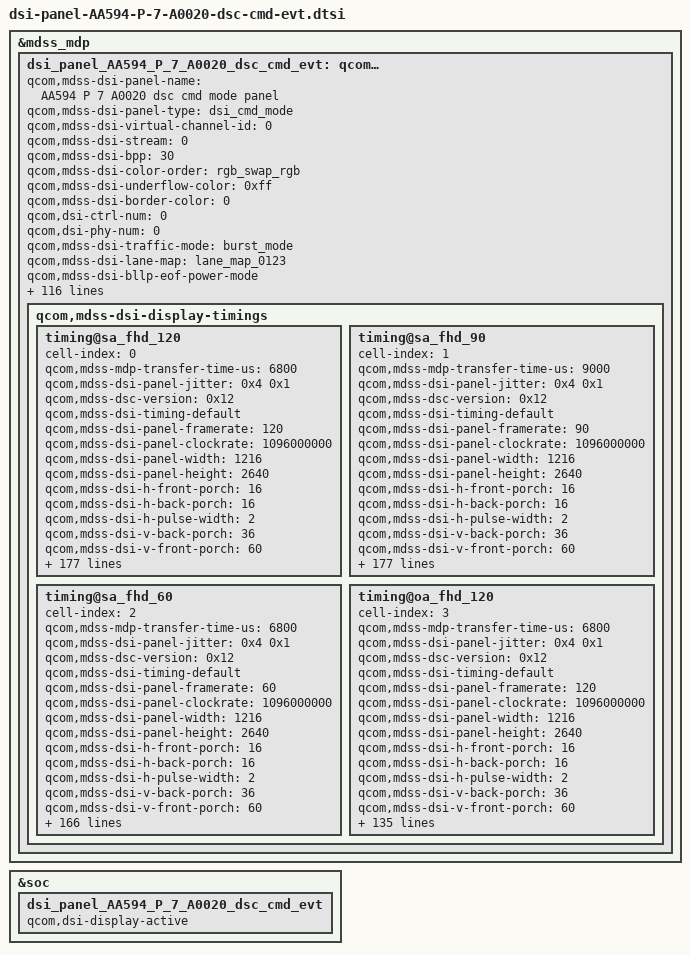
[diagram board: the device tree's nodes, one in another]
&mdss_mdp {
	dsi_panel_AA594_P_7_A0020_dsc_cmd_evt: qcom,mdss_dsi_panel_AA594_P_7_A0020_dsc_cmd_evt {
		qcom,mdss-dsi-panel-name = "AA594 P 7 A0020 dsc cmd mode panel";
		qcom,mdss-dsi-panel-type = "dsi_cmd_mode";
		qcom,mdss-dsi-virtual-channel-id = <0>;
		qcom,mdss-dsi-stream = <0>;
		qcom,mdss-dsi-bpp = <30>;
		qcom,mdss-dsi-color-order = "rgb_swap_rgb";
		qcom,mdss-dsi-underflow-color = <0xff>;
		qcom,mdss-dsi-border-color = <0>;
		qcom,dsi-ctrl-num = <0>;
		qcom,dsi-phy-num = <0>;
		qcom,mdss-dsi-traffic-mode = "burst_mode";
		qcom,mdss-dsi-lane-map = "lane_map_0123";
		qcom,mdss-dsi-bllp-eof-power-mode;
		qcom,mdss-dsi-bllp-power-mode;
		qcom,mdss-dsi-lane-0-state;
		qcom,mdss-dsi-lane-1-state;
		qcom,mdss-dsi-lane-2-state;
		qcom,mdss-dsi-lane-3-state;
		qcom,mdss-dsi-dma-trigger = "trigger_sw";
		qcom,mdss-dsi-dma-schedule-line = <1>;
		qcom,mdss-dsi-dma-schedule-window = <10>;
		qcom,mdss-dsi-mdp-trigger = "none";
		qcom,mdss-dsi-reset-sequence = <1 10>, <0 5>, <1 25>;
		qcom,mdss-dsi-te-pin-select = <1>;
		qcom,mdss-dsi-te-dcs-command = <1>;
		qcom,mdss-pan-physical-width-dimension = <67>;
		qcom,mdss-pan-physical-height-dimension = <146>;
		qcom,mdss-dsi-init-delay-us = <1000>;
		qcom,mdss-dsi-te-check-enable;
		qcom,mdss-dsi-te-using-te-pin;
		//qcom,mdss-dsi-lp11-init;
		qcom,mdss-dsi-wr-mem-start = <0x2C>;
		qcom,mdss-dsi-wr-mem-continue = <0x3C>;
		qcom,mdss-dsi-panel-jitter = <0x4 0x1>;
		qcom,mdss-bl-high2bit;
		/* HDR Setting */
		qcom,mdss-dsi-panel-hdr-enabled;
		qcom,mdss-dsi-panel-hdr-color-primaries = <15635 16450 34000 16000 13250 34500 7500 3000>;
		//update for [MPC15]android.mediapc.cts.PerformanceClassTest#testDisplayHdr pass
		//qcom,mdss-dsi-panel-peak-brightness = <5400000>;
		qcom,mdss-dsi-panel-peak-brightness = <20000000>;
		qcom,mdss-dsi-panel-average-brightness = <2000000>;
		qcom,mdss-dsi-panel-blackness-level = <4000>;

		qcom,mdss-dsi-display-timings {
			timing@sa_fhd_120 {
				#include "dsi-panel-AA594-P-7-A0020-common.dtsi"
				#include "dsi-panel-AA594-P-7-A0020-common-effect.dtsi"
				cell-index = <0>;
				qcom,mdss-mdp-transfer-time-us = <6800>;
				qcom,mdss-dsi-panel-jitter = <0x4 0x1>;
				qcom,mdss-dsc-version = <0x12>;
				qcom,mdss-dsi-timing-default;
				qcom,mdss-dsi-panel-framerate = <120>;
				qcom,mdss-dsi-panel-clockrate = <1096000000>;
				qcom,mdss-dsi-panel-width = <1216>;
				qcom,mdss-dsi-panel-height = <2640>;

				qcom,mdss-dsi-h-front-porch = <16>;
				qcom,mdss-dsi-h-back-porch = <16>;
				qcom,mdss-dsi-h-pulse-width = <2>;
				qcom,mdss-dsi-v-back-porch = <36>;
				qcom,mdss-dsi-v-front-porch = <60>;
				qcom,mdss-dsi-v-pulse-width = <4>;
				qcom,mdss-dsi-h-sync-pulse = <0>;

				oplus,ofp-backlight-on-period = <1>;

				qcom,mdss-dsi-timing-switch-command = [
					/* Switch To 120Hz(Normal 1+18 pulse) */
					39 00 00 40 00 00 04 FF 5A A5 53
					39 00 00 40 00 00 03 85 CC E1
					39 00 00 40 00 00 04 FF 5A A5 00
					15 00 00 40 00 00 02 60 00 //120hz
					39 00 00 40 00 00 04 FF 5A A5 2D
					39 00 00 40 00 00 03 83 00 00
					15 00 00 40 00 00 02 F2 00
					39 00 00 00 00 00 04 FF 5A A5 00
				];
				qcom,mdss-dsi-on-command = [
					/* DSC setting */
					39 00 00 40 00 00 04 FF 5A A5 1F
					39 00 00 40 00 00 04 83 2C 00 4E
					39 00 00 40 00 00 04 84 1B 00 4E
					39 00 00 00 00 00 04 85 35 00 4E
					39 00 00 40 00 00 04 FF 5A A5 07
					15 00 00 40 00 00 02 8A 01
					39 00 00 40 00 00 03 8B 21 A0
					39 00 00 40 00 00 64 80 00 00 00 00 00
							12 00 00 AB 21 00 0A 50 04 C0 00 14
							02 60 02 60 01 55 01 D3 00 0A 01 08
							00 33 00 0D 05 7A 19 5A 08 00 0B F0
							07 10 20 00 06 0F 0F 33 0E 1C 2A 38
							46 54 62 69 70 77 79 7B 7D 7E 00 82
							11 40 19 C0 22 3E 32 7C 3A BA 3A F8
							3B 38 3B 38 3B 76 4B 76 4B 74 4B 74
							5B B4 73 F4 01 00 00 00 00 00
					15 00 00 40 00 00 02 91 03
					39 00 00 40 00 00 04 FF 5A A5 14
					15 00 00 40 00 00 02 80 00
					15 00 00 40 00 00 02 82 01
					39 00 00 00 00 00 04 FF 5A A5 00
					/* Common setting */
					39 00 00 40 00 00 04 FF 5A A5 08
					15 00 00 40 00 00 02 C8 62
					39 00 00 40 00 00 04 FF 5A A5 21
					15 00 00 40 00 00 02 A4 18
					39 00 00 40 00 00 04 FF 5A A5 00
					15 00 00 40 00 00 02 5E 01
					15 00 00 40 00 00 02 60 00
					15 00 00 40 00 00 02 61 07
					15 00 00 40 00 00 02 6D 01
					05 00 00 40 00 00 01 35
					15 00 00 40 00 00 02 53 20
					39 00 00 40 00 00 04 FF 5A A5 06
					15 00 00 40 00 00 02 C6 01 //1bit ESD Check
					39 00 00 40 00 00 04 FF 5A A5 08
					15 00 00 40 00 00 02 D2 05
					15 00 00 40 00 00 02 D3 01
					39 00 00 40 00 00 0A ED FF FF FF 0F 07 FF CF 45 FF //Golden CRC
					39 00 00 40 00 00 09 EE FF FD C1 F8 21 00 80 50
					39 00 00 40 00 00 04 FF 5A A5 20
					15 00 00 40 00 00 02 BC 07 //GPO1 TEST TE
					15 00 00 40 00 00 02 BD 06 //GPO0 SYNC TE
					39 00 00 00 00 00 04 FF 5A A5 00
					/* Corner/Hole/Edge OFF */
					39 00 00 40 00 00 04 FF 5A A5 17
					15 00 00 40 00 00 02 A0 0C
					39 00 00 00 00 00 04 FF 5A A5 00
					/* Switch To 120Hz(Normal 1+18 pulse) */
					39 00 00 40 00 00 04 FF 5A A5 53
					39 00 00 40 00 00 03 85 CC E1
					39 00 00 40 00 00 04 FF 5A A5 00
					15 00 00 40 00 00 02 60 00 //120hz
					39 00 00 40 00 00 04 FF 5A A5 2D
					39 00 00 40 00 00 03 83 00 00
					15 00 00 40 00 00 02 F2 00
					39 00 00 00 00 00 04 FF 5A A5 00
					39 00 00 40 00 00 04 FF 5A A5 1E
					15 00 00 40 00 00 02 9B 02
					39 00 00 00 00 00 04 FF 5A A5 00
					05 00 00 00 78 00 01 11
					05 00 00 00 00 00 01 29
				];
				qcom,mdss-dsi-optimize-on-command = [
					/* DSC setting */
					39 00 00 40 00 00 04 FF 5A A5 07
					15 00 00 40 00 00 02 8A 01
					39 00 00 40 00 00 03 8B 21 A0
					39 00 00 40 00 00 64 80 00 00 00 00 00
							12 00 00 AB 21 00 0A 50 04 C0 00 14
							02 60 02 60 01 55 01 D3 00 0A 01 08
							00 33 00 0D 05 7A 19 5A 08 00 0B F0
							07 10 20 00 06 0F 0F 33 0E 1C 2A 38
							46 54 62 69 70 77 79 7B 7D 7E 00 82
							11 40 19 C0 22 3E 32 7C 3A BA 3A F8
							3B 38 3B 38 3B 76 4B 76 4B 74 4B 74
							5B B4 73 F4 01 00 00 00 00 00
					15 00 00 40 00 00 02 91 03
					39 00 00 40 00 00 04 FF 5A A5 14
					15 00 00 40 00 00 02 80 00
					15 00 00 40 00 00 02 82 01
					39 00 00 00 00 00 04 FF 5A A5 00
					/* Common setting */
					39 00 00 40 00 00 04 FF 5A A5 08
					15 00 00 40 00 00 02 C8 62
					39 00 00 40 00 00 04 FF 5A A5 21
					15 00 00 40 00 00 02 A4 18
					39 00 00 40 00 00 04 FF 5A A5 00
					15 00 00 40 00 00 02 5E 01
					15 00 00 40 00 00 02 60 00
					15 00 00 40 00 00 02 61 07
					15 00 00 40 00 00 02 6D 01
					05 00 00 40 00 00 01 35
					15 00 00 40 00 00 02 53 20
					39 00 00 40 00 00 04 FF 5A A5 06
					15 00 00 40 00 00 02 C6 01 //1bit ESD Check
					39 00 00 40 00 00 04 FF 5A A5 08
					15 00 00 40 00 00 02 D2 05
					15 00 00 40 00 00 02 D3 01
					39 00 00 40 00 00 0A ED FF FF FF 0F 07 FF CF 45 FF //Golden CRC
					39 00 00 40 00 00 09 EE FF FD C1 F8 21 00 80 50
					39 00 00 40 00 00 04 FF 5A A5 20
					15 00 00 40 00 00 02 BC 07 //GPO1 TEST TE
					15 00 00 40 00 00 02 BD 06 //GPO0 SYNC TE
					39 00 00 00 00 00 04 FF 5A A5 00
					/* Corner/Hole/Edge OFF */
					39 00 00 40 00 00 04 FF 5A A5 17
					15 00 00 40 00 00 02 A0 0C
					39 00 00 00 00 00 04 FF 5A A5 00
					/* Switch To 120Hz(Normal 1+18 pulse) */
					39 00 00 40 00 00 04 FF 5A A5 4E
					39 00 00 40 00 00 5B CF 00 14 14 14 14 14 08 88 88 00 00 00 00 00 00 00 00 00 00 08 08 08 08 08 08 88 88 00 00 00 00 00 00 00 00 00 00 08 08 08 08 08 08 88 88 00 00 00 00 00 00 00 00 00 00 00 00 00 00 00 08 88 88 00 00 00 00 00 00 00 00 00 00 00 00 00 00 00 08 88 88 00 00 00 00 00 00 00 00 00
					39 00 00 40 00 00 5B D0 00 0F 0F 0F 0F 0F 08 88 88 00 00 00 00 00 00 00 00 00 00 0B 0B 0B 0B 0B 08 88 88 00 00 00 00 00 00 00 00 00 00 0B 0B 0B 0B 0B 08 88 88 00 00 00 00 00 00 00 00 00 00 07 07 07 07 07 08 88 88 00 00 00 00 00 00 00 00 00 00 07 07 07 07 07 08 88 88 00 00 00 00 00 00 00 00 00
					39 00 00 40 00 00 04 FF 5A A5 53
					39 00 00 40 00 00 03 85 CC E1
					39 00 00 40 00 00 04 FF 5A A5 00
					15 00 00 40 00 00 02 60 00 //120Hz
					39 00 00 40 00 00 04 FF 5A A5 2D
					39 00 00 40 00 00 03 83 00 00
					15 00 00 40 00 00 02 F2 00
					39 00 00 00 00 00 04 FF 5A A5 00
					39 00 00 40 00 00 04 FF 5A A5 1E
					39 00 00 40 00 00 04 C1 10 9C C9
					39 00 00 40 00 00 08 C2 FF FF FF 60 60 63 63
					39 00 00 40 00 00 04 FF 5A A5 1F
					39 00 00 40 00 00 07 C1 00 00 00 00 1F FF
					39 00 00 00 00 00 1F C2 AB D7 D8 E2 1F FF 25 27 FF FF FF FF FF FF FF FF FF FF FF FF FF FF FF FF FF FF FF FF FF FF
					05 00 00 00 78 00 01 11
					05 00 00 00 00 00 01 29
				];
				qcom,mdss-dsi-off-command = [
					05 00 00 00 14 00 01 28
					05 00 00 00 78 00 01 10
				];
				qcom,mdss-dsi-hbm-off-command = [
					39 00 00 00 00 00 03 51 0D BB
				];
				qcom,mdss-dsi-hbm-on-command = [
					39 00 00 00 00 00 03 51 0E E0
				];
				/* pwm */
				qcom,mdss-dsi-pwm-switch-mode1-command = [
					39 00 00 40 00 00 04 FF 5A A5 51
					39 00 00 40 00 00 07 A0 AF AF AF AF 22 22
					39 00 00 40 00 00 07 A1 AF AF AF AF 22 22
					39 00 00 40 00 00 07 A2 AF AF AF AF 22 22
					39 00 00 40 00 00 07 A3 AF AF AF AF 22 22
					39 00 00 40 00 00 07 A4 AF AF AF AF 22 22
					39 00 00 40 00 00 07 A5 AF AF B9 B9 22 22
					39 00 00 40 00 00 07 A6 B3 B3 B6 B6 22 22
					39 00 00 40 00 00 07 A7 D4 D4 00 00 22 00
					39 00 00 40 00 00 04 FF 5A A5 52
					39 00 00 40 00 00 07 80 5E 2C B4 AA 11 00
					39 00 00 40 00 00 07 81 A0 A0 96 96 00 00
					39 00 00 40 00 00 07 82 8C 8C 82 82 00 00
					39 00 00 40 00 00 07 83 82 78 78 6E 00 00
					39 00 00 40 00 00 07 84 6E 64 64 64 00 00
					39 00 00 40 00 00 07 85 5A 5A 5C 5C 00 00
					39 00 00 40 00 00 07 86 5D 5D 5D 5D 00 00
					39 00 00 40 00 00 07 87 52 52 00 00 11 00
					39 00 00 40 00 00 04 FF 5A A5 00
					15 00 00 40 00 00 02 60 00 //120hz
					39 00 00 40 00 00 04 FF 5A A5 2D
					39 00 00 40 00 00 03 83 00 00
					15 00 00 40 00 00 02 F2 00
					39 00 00 40 00 00 04 FF 5A A5 53
					39 00 00 40 00 00 03 85 CC E1
					39 00 00 00 00 00 04 FF 5A A5 00
				];
				qcom,mdss-dsi-pwm-switch-mode2-command = [
					39 00 00 40 00 00 04 FF 5A A5 51
					39 00 00 40 00 00 07 A0 AF AF AF AF 22 22
					39 00 00 40 00 00 07 A1 AF AF AF AF 22 22
					39 00 00 40 00 00 07 A2 AF AF AF AF 22 22
					39 00 00 40 00 00 07 A3 AF AF AF AF 22 22
					39 00 00 40 00 00 07 A4 AF AF AF AF 22 22
					39 00 00 40 00 00 07 A5 AF AF BC BC 22 22
					39 00 00 40 00 00 07 A6 C0 C0 C0 C0 22 22
					39 00 00 40 00 00 07 A7 CA CA 00 00 22 00
					39 00 00 40 00 00 04 FF 5A A5 52
					39 00 00 40 00 00 07 80 5E 2C B4 AA 11 00
					39 00 00 40 00 00 07 81 A0 A0 96 96 00 00
					39 00 00 40 00 00 07 82 8C 8C 82 82 00 00
					39 00 00 40 00 00 07 83 82 78 78 6E 00 00
					39 00 00 40 00 00 07 84 6E 64 64 64 00 00
					39 00 00 40 00 00 07 85 5A 5A 5B 5B 00 00
					39 00 00 40 00 00 07 86 5C 5C 5C 5C 00 00
					39 00 00 40 00 00 07 87 4D 4D 00 00 11 00
					39 00 00 40 00 00 04 FF 5A A5 53
					39 00 00 40 00 00 03 85 CC E3
					39 00 00 40 00 00 04 FF 5A A5 00
					15 00 00 40 00 00 02 60 01 //DC 120hz
					39 00 00 40 00 00 04 FF 5A A5 2D
					39 00 00 40 00 00 03 84 00 00
					15 00 00 40 00 00 02 F2 00
					39 00 00 00 00 00 04 FF 5A A5 00
				];
				qcom,mdss-dsi-timming-switch-pwm-mode2-command = [
					39 00 00 40 00 00 04 FF 5A A5 53
					39 00 00 40 00 00 03 85 CC E3
					39 00 00 40 00 00 04 FF 5A A5 00
					15 00 00 40 00 00 02 60 01 //DC 120Hz
					39 00 00 40 00 00 04 FF 5A A5 2D
					39 00 00 40 00 00 03 84 00 00
					15 00 00 40 00 00 02 F2 00
					39 00 00 00 00 00 04 FF 5A A5 00
				];
				qcom,mdss-dsi-pwm-switch-mode2-panel-on-command = [
					39 00 00 40 00 00 04 FF 5A A5 51
					39 00 00 40 00 00 07 A0 AF AF AF AF 22 22
					39 00 00 40 00 00 07 A1 AF AF AF AF 22 22
					39 00 00 40 00 00 07 A2 AF AF AF AF 22 22
					39 00 00 40 00 00 07 A3 AF AF AF AF 22 22
					39 00 00 40 00 00 07 A4 AF AF AF AF 22 22
					39 00 00 40 00 00 07 A5 AF AF BC BC 22 22
					39 00 00 40 00 00 07 A6 C0 C0 C0 C0 22 22
					39 00 00 40 00 00 07 A7 CA CA 00 00 22 00
					39 00 00 40 00 00 04 FF 5A A5 52
					39 00 00 40 00 00 07 80 5E 2C B4 AA 11 00
					39 00 00 40 00 00 07 81 A0 A0 96 96 00 00
					39 00 00 40 00 00 07 82 8C 8C 82 82 00 00
					39 00 00 40 00 00 07 83 82 78 78 6E 00 00
					39 00 00 40 00 00 07 84 6E 64 64 64 00 00
					39 00 00 40 00 00 07 85 5A 5A 5B 5B 00 00
					39 00 00 40 00 00 07 86 5C 5C 5C 5C 00 00
					39 00 00 40 00 00 07 87 4D 4D 00 00 11 00
					39 00 00 40 00 00 04 FF 5A A5 53
					39 00 00 40 00 00 03 85 CC E3
					39 00 00 40 00 00 04 FF 5A A5 00
					15 00 00 40 00 00 02 60 01 //DC 120hz
					39 00 00 40 00 00 04 FF 5A A5 2D
					39 00 00 40 00 00 03 84 00 00
					15 00 00 40 00 00 02 F2 00
					39 00 00 00 00 00 04 FF 5A A5 00
				];
				qcom,mdss-dsi-lhbm-pressed-icon-on-command = [
					39 00 00 40 00 00 04 FF 5A A5 00
					15 00 00 40 00 00 02 96 09
					15 00 00 40 00 00 02 97 5B
					39 00 00 00 00 00 02 6E 03
				];
				qcom,mdss-dsi-lhbm-pressed-icon-off-command = [
					39 00 00 40 00 00 04 FF 5A A5 00
					39 00 00 00 00 00 02 6E 00
				];
				qcom,mdss-dsi-lp1-command = [
					39 00 00 40 00 00 04 FF 5A A5 00
					15 00 00 40 00 00 01 39
					39 00 00 40 00 00 04 FF 5A A5 2D
					15 00 00 40 00 00 03 8A 00 00
					/* AOD lv switch */
					39 00 00 40 00 00 04 FF 5A A5 00
					39 00 00 00 00 00 05 51 0D BB 0D BB
				];
				qcom,mdss-dsi-nolp-command = [
					39 00 00 40 00 00 04 FF 5A A5 00
					15 00 00 40 00 00 01 38
					39 00 00 00 00 00 05 51 00 00 00 00
				];
				qcom,mdss-dsi-aod-off-pwm-mode2-command = [
				];
				qcom,mdss-dsi-aod-off-compensation-command = [

				];
				qcom,mdss-dsi-aod-off-compensation-onepulse-command = [

				];
				qcom,mdss-dsi-aod-high-mode-command = [
					39 00 00 40 00 00 04 FF 5A A5 00
					39 00 00 00 00 00 05 51 0D BB 0D BB
				];
				qcom,mdss-dsi-aod-low-mode-command = [
					39 00 00 40 00 00 04 FF 5A A5 00
					39 00 00 00 00 00 05 51 0D BB 00 03
				];
				qcom,mdss-dsi-ultra-low-power-aod-on-command = [
					39 00 00 40 00 00 04 FF 5A A5 2D
					39 00 00 40 00 00 03 8A 02 00
					39 00 00 00 00 00 04 FF 5A A5 00
				];
				qcom,mdss-dsi-ultra-low-power-aod-off-command = [
					39 00 00 40 00 00 04 FF 5A A5 2D
					39 00 00 40 00 00 03 8A 00 00
					39 00 00 00 00 00 04 FF 5A A5 00
				];
				qcom,mdss-dsi-hbm-max-command = [
					39 00 00 00 00 00 03 51 10 ED
				];
				qcom,mdss-dsi-hbm-exit-max-command = [
					39 00 00 00 00 00 03 51 0F FE
				];
				qcom,mdss-dsi-lp1-command-state = "dsi_hs_mode";
				qcom,mdss-dsi-nolp-command-state = "dsi_hs_mode";
				qcom,mdss-dsi-aod-off-pwm-mode2-command-state = "dsi_hs_mode";
				qcom,mdss-dsi-aod-off-compensation-command-state = "dsi_lp_mode";
				qcom,mdss-dsi-aod-off-compensation-onepulse-command-state = "dsi_lp_mode";
				qcom,mdss-dsi-nolp-hpwm-command-state = "dsi_lp_mode";
				qcom,mdss-dsi-hbm-on-command-state = "dsi_hs_mode";
				qcom,mdss-dsi-hbm-off-command-state = "dsi_hs_mode";
				qcom,mdss-dsi-panel-read-register-open-state = "dsi_lp_mode";
				qcom,mdss-dsi-panel-read-register-close-state = "dsi_lp_mode";
				qcom,mdss-dsi-lhbm-pressed-icon-gamma-command-state = "dsi_lp_mode";
				qcom,mdss-dsi-lhbm-pressed-icon-grayscale-command-state = "dsi_lp_mode";
				qcom,mdss-dsi-lhbm-pressed-icon-on-command-state = "dsi_lp_mode";
				qcom,mdss-dsi-lhbm-pressed-icon-off-command-state = "dsi_lp_mode";
				qcom,mdss-dsi-lhbm-dbv-alpha-command-state = "dsi_hs_mode";

				qcom,mdss-dsi-reset-scanline-command-state = "dsi_hs_mode";
				qcom,mdss-dsi-recovery-scanline-command-state = "dsi_hs_mode";

				qcom,mdss-dsi-osc-track-on-command-state = "dsi_hs_mode";
				qcom,mdss-dsi-osc-track-off-command-state = "dsi_hs_mode";
				qcom,mdss-dsi-hbm-max-command-state = "dsi_hs_mode";
				qcom,mdss-dsi-hbm-exit-max-command-state = "dsi_hs_mode";

				qcom,lm-split = <608 608>;
				qcom,compression-mode = "dsc";
				qcom,mdss-dsc-encoders = <2>;
				qcom,mdss-dsc-slice-height = <20>;
				qcom,mdss-dsc-slice-width = <608>;
				qcom,mdss-dsc-slice-per-pkt = <2>;
				qcom,mdss-dsc-bit-per-component = <10>;
				qcom,mdss-dsc-bit-per-pixel = <8>;
				qcom,mdss-dsc-block-prediction-enable;
			};
			timing@sa_fhd_90 {
				#include "dsi-panel-AA594-P-7-A0020-common.dtsi"
				#include "dsi-panel-AA594-P-7-A0020-common-effect.dtsi"
				cell-index = <1>;
				qcom,mdss-mdp-transfer-time-us = <9000>;
				qcom,mdss-dsi-panel-jitter = <0x4 0x1>;
				qcom,mdss-dsc-version = <0x12>;
				qcom,mdss-dsi-timing-default;
				qcom,mdss-dsi-panel-framerate = <90>;
				qcom,mdss-dsi-panel-clockrate = <1096000000>;
				qcom,mdss-dsi-panel-width = <1216>;
				qcom,mdss-dsi-panel-height = <2640>;

				qcom,mdss-dsi-h-front-porch = <16>;
				qcom,mdss-dsi-h-back-porch = <16>;
				qcom,mdss-dsi-h-pulse-width = <2>;
				qcom,mdss-dsi-v-back-porch = <36>;
				qcom,mdss-dsi-v-front-porch = <60>;
				qcom,mdss-dsi-v-pulse-width = <4>;
				qcom,mdss-dsi-h-sync-pulse = <0>;

				oplus,ofp-backlight-on-period = <1>;
				oplus,apollo-panel-async-bl-delay = <6000>;

				qcom,mdss-dsi-timing-switch-command = [
					/* Switch To 90Hz (Normal 1+24 pulse) */
					39 00 00 40 00 00 04 FF 5A A5 53
					39 00 00 40 00 00 03 85 CC E1
					39 00 00 40 00 00 04 FF 5A A5 00
					15 00 00 40 00 00 02 60 02 //90hz
					39 00 00 40 00 00 04 FF 5A A5 2D
					39 00 00 40 00 00 03 85 00 00
					15 00 00 40 00 00 02 F2 00
					39 00 00 00 00 00 04 FF 5A A5 00
				];
				qcom,mdss-dsi-on-command = [
					/* DSC setting */
					39 00 00 40 00 00 04 FF 5A A5 1F
					39 00 00 40 00 00 04 83 2C 00 4E
					39 00 00 40 00 00 04 84 1B 00 4E
					39 00 00 00 00 00 04 85 35 00 4E
					39 00 00 40 00 00 04 FF 5A A5 07
					15 00 00 40 00 00 02 8A 01
					39 00 00 40 00 00 03 8B 21 A0
					39 00 00 40 00 00 64 80 00 00 00 00 00
							12 00 00 AB 21 00 0A 50 04 C0 00 14
							02 60 02 60 01 55 01 D3 00 0A 01 08
							00 33 00 0D 05 7A 19 5A 08 00 0B F0
							07 10 20 00 06 0F 0F 33 0E 1C 2A 38
							46 54 62 69 70 77 79 7B 7D 7E 00 82
							11 40 19 C0 22 3E 32 7C 3A BA 3A F8
							3B 38 3B 38 3B 76 4B 76 4B 74 4B 74
							5B B4 73 F4 01 00 00 00 00 00
					15 00 00 40 00 00 02 91 03
					39 00 00 40 00 00 04 FF 5A A5 14
					15 00 00 40 00 00 02 80 00
					15 00 00 40 00 00 02 82 01
					39 00 00 00 00 00 04 FF 5A A5 00
					/* Common setting */
					39 00 00 40 00 00 04 FF 5A A5 08
					15 00 00 40 00 00 02 C8 62
					39 00 00 40 00 00 04 FF 5A A5 21
					15 00 00 40 00 00 02 A4 18
					39 00 00 40 00 00 04 FF 5A A5 00
					15 00 00 40 00 00 02 5E 01
					15 00 00 40 00 00 02 60 00
					15 00 00 40 00 00 02 61 07
					15 00 00 40 00 00 02 6D 01
					05 00 00 40 00 00 01 35
					15 00 00 40 00 00 02 53 20
					39 00 00 40 00 00 04 FF 5A A5 06
					15 00 00 40 00 00 02 C6 01 //1bit ESD Check
					39 00 00 40 00 00 04 FF 5A A5 08
					15 00 00 40 00 00 02 D2 05
					15 00 00 40 00 00 02 D3 01
					39 00 00 40 00 00 0A ED FF FF FF 0F 07 FF CF 45 FF //Golden CRC
					39 00 00 40 00 00 09 EE FF FD C1 F8 21 00 80 50
					39 00 00 40 00 00 04 FF 5A A5 20
					15 00 00 40 00 00 02 BC 07 //GPO1 TEST TE
					15 00 00 40 00 00 02 BD 06 //GPO0 SYNC TE
					39 00 00 00 00 00 04 FF 5A A5 00
					/* Corner/Hole/Edge OFF */
					39 00 00 40 00 00 04 FF 5A A5 17
					15 00 00 40 00 00 02 A0 0C
					39 00 00 00 00 00 04 FF 5A A5 00
					/* Switch To 90Hz (Normal 1+24 pulse) */
					39 00 00 40 00 00 04 FF 5A A5 53
					39 00 00 40 00 00 03 85 CC E1
					39 00 00 40 00 00 04 FF 5A A5 00
					15 00 00 40 00 00 02 60 02 //90hz
					39 00 00 40 00 00 04 FF 5A A5 2D
					39 00 00 40 00 00 03 85 00 00
					15 00 00 40 00 00 02 F2 00
					39 00 00 00 00 00 04 FF 5A A5 00
					39 00 00 40 00 00 04 FF 5A A5 1E
					15 00 00 40 00 00 02 9B 02
					39 00 00 00 00 00 04 FF 5A A5 00
					05 00 00 00 78 00 01 11
					05 00 00 00 00 00 01 29
				];
				qcom,mdss-dsi-optimize-on-command = [
					/* DSC setting */
					39 00 00 40 00 00 04 FF 5A A5 07
					15 00 00 40 00 00 02 8A 01
					39 00 00 40 00 00 03 8B 21 A0
					39 00 00 40 00 00 64 80 00 00 00 00 00
							12 00 00 AB 21 00 0A 50 04 C0 00 14
							02 60 02 60 01 55 01 D3 00 0A 01 08
							00 33 00 0D 05 7A 19 5A 08 00 0B F0
							07 10 20 00 06 0F 0F 33 0E 1C 2A 38
							46 54 62 69 70 77 79 7B 7D 7E 00 82
							11 40 19 C0 22 3E 32 7C 3A BA 3A F8
							3B 38 3B 38 3B 76 4B 76 4B 74 4B 74
							5B B4 73 F4 01 00 00 00 00 00
					15 00 00 40 00 00 02 91 03
					39 00 00 40 00 00 04 FF 5A A5 14
					15 00 00 40 00 00 02 80 00
					15 00 00 40 00 00 02 82 01
					39 00 00 00 00 00 04 FF 5A A5 00
					/* Common setting */
					39 00 00 40 00 00 04 FF 5A A5 08
					15 00 00 40 00 00 02 C8 62
					39 00 00 40 00 00 04 FF 5A A5 21
					15 00 00 40 00 00 02 A4 18
					39 00 00 40 00 00 04 FF 5A A5 00
					15 00 00 40 00 00 02 5E 01
					15 00 00 40 00 00 02 60 00
					15 00 00 40 00 00 02 61 07
					15 00 00 40 00 00 02 6D 01
					05 00 00 40 00 00 01 35
					15 00 00 40 00 00 02 53 20
					39 00 00 40 00 00 04 FF 5A A5 06
					15 00 00 40 00 00 02 C6 01 //1bit ESD Check
					39 00 00 40 00 00 04 FF 5A A5 08
					15 00 00 40 00 00 02 D2 05
					15 00 00 40 00 00 02 D3 01
					39 00 00 40 00 00 0A ED FF FF FF 0F 07 FF CF 45 FF //Golden CRC
					39 00 00 40 00 00 09 EE FF FD C1 F8 21 00 80 50
					39 00 00 40 00 00 04 FF 5A A5 20
					15 00 00 40 00 00 02 BC 07 //GPO1 TEST TE
					15 00 00 40 00 00 02 BD 06 //GPO0 SYNC TE
					39 00 00 00 00 00 04 FF 5A A5 00
					/* Corner/Hole/Edge OFF */
					39 00 00 40 00 00 04 FF 5A A5 17
					15 00 00 40 00 00 02 A0 0C
					39 00 00 00 00 00 04 FF 5A A5 00
					/* Switch To 90Hz (Normal 1+24 pulse) */
					39 00 00 40 00 00 04 FF 5A A5 4E
					39 00 00 40 00 00 5B CF 00 14 14 14 14 14 08 88 88 00 00 00 00 00 00 00 00 00 00 0A 0A 0A 0A 0A 08 88 88 00 00 00 00 00 00 00 00 00 00 0A 0A 0A 0A 0A 08 88 88 00 00 00 00 00 00 00 00 00 00 18 18 18 18 18 08 88 88 00 00 00 00 00 00 00 00 00 00 18 18 18 18 18 08 88 88 00 00 00 00 00 00 00 00 00
					39 00 00 40 00 00 5B D0 00 0F 0F 0F 0F 0F 08 88 88 00 00 00 00 00 00 00 00 00 00 0B 0B 0B 0B 0B 08 88 88 00 00 00 00 00 00 00 00 00 00 0B 0B 0B 0B 0B 08 88 88 00 00 00 00 00 00 00 00 00 00 0B 0B 0B 0B 0B 08 88 88 00 00 00 00 00 00 00 00 00 00 0B 0B 0B 0B 0B 08 88 88 00 00 00 00 00 00 00 00 00
					39 00 00 40 00 00 04 FF 5A A5 53
					39 00 00 40 00 00 03 85 CC E1
					39 00 00 40 00 00 04 FF 5A A5 00
					15 00 00 40 00 00 02 60 02 //90Hz
					39 00 00 40 00 00 04 FF 5A A5 2D
					39 00 00 40 00 00 03 85 00 00
					15 00 00 40 00 00 02 F2 00
					39 00 00 00 00 00 04 FF 5A A5 00
					39 00 00 40 00 00 04 FF 5A A5 1E
					39 00 00 40 00 00 04 C1 10 9C C9
					39 00 00 40 00 00 08 C2 FF FF FF 60 60 63 63
					39 00 00 40 00 00 04 FF 5A A5 1F
					39 00 00 40 00 00 07 C1 00 00 00 00 1F FF
					39 00 00 00 00 00 1F C2 AB D7 D8 E2 1F FF 25 27 FF FF FF FF FF FF FF FF FF FF FF FF FF FF FF FF FF FF FF FF FF FF
					05 00 00 00 78 00 01 11
					05 00 00 00 00 00 01 29
				];
				qcom,mdss-dsi-off-command=[
					05 00 00 00 14 00 01 28
					05 00 00 00 78 00 01 10
				];
				qcom,mdss-dsi-hbm-off-command = [
					39 00 00 00 00 00 03 51 0D BB
				];
				qcom,mdss-dsi-hbm-on-command = [
					39 00 00 00 00 00 03 51 0E E0
				];
				/* pwm */
				qcom,mdss-dsi-pwm-switch-mode1-command= [
					39 00 00 40 00 00 04 FF 5A A5 51
					39 00 00 40 00 00 07 A0 AF AF AF AF 22 22
					39 00 00 40 00 00 07 A1 AF AF AF AF 22 22
					39 00 00 40 00 00 07 A2 AF AF AF AF 22 22
					39 00 00 40 00 00 07 A3 AF AF AF AF 22 22
					39 00 00 40 00 00 07 A4 AF AF AF AF 22 22
					39 00 00 40 00 00 07 A5 AF AF B9 B9 22 22
					39 00 00 40 00 00 07 A6 B3 B3 B6 B6 22 22
					39 00 00 40 00 00 07 A7 D4 D4 00 00 22 00
					39 00 00 40 00 00 04 FF 5A A5 52
					39 00 00 40 00 00 07 80 5E 2C B4 AA 11 00
					39 00 00 40 00 00 07 81 A0 A0 96 96 00 00
					39 00 00 40 00 00 07 82 8C 8C 82 82 00 00
					39 00 00 40 00 00 07 83 82 78 78 6E 00 00
					39 00 00 40 00 00 07 84 6E 64 64 64 00 00
					39 00 00 40 00 00 07 85 5A 5A 5C 5C 00 00
					39 00 00 40 00 00 07 86 5D 5D 5D 5D 00 00
					39 00 00 40 00 00 07 87 52 52 00 00 11 00
					39 00 00 40 00 00 04 FF 5A A5 53
					39 00 00 40 00 00 03 85 CC E1
					39 00 00 40 00 00 04 FF 5A A5 00
					15 00 00 40 00 00 02 60 02 //90hz
					39 00 00 40 00 00 04 FF 5A A5 2D
					39 00 00 40 00 00 03 85 00 00
					15 00 00 40 00 00 02 F2 00
					39 00 00 00 00 00 04 FF 5A A5 00
				];
				qcom,mdss-dsi-pwm-switch-mode2-command = [
					39 00 00 40 00 00 04 FF 5A A5 51
					39 00 00 40 00 00 07 A0 AF AF AF AF 22 22
					39 00 00 40 00 00 07 A1 AF AF AF AF 22 22
					39 00 00 40 00 00 07 A2 AF AF AF AF 22 22
					39 00 00 40 00 00 07 A3 AF AF AF AF 22 22
					39 00 00 40 00 00 07 A4 AF AF AF AF 22 22
					39 00 00 40 00 00 07 A5 AF AF BC BC 22 22
					39 00 00 40 00 00 07 A6 C0 C0 C0 C0 22 22
					39 00 00 40 00 00 07 A7 CA CA 00 00 22 00
					39 00 00 40 00 00 04 FF 5A A5 52
					39 00 00 40 00 00 07 80 5E 2C B4 AA 11 00
					39 00 00 40 00 00 07 81 A0 A0 96 96 00 00
					39 00 00 40 00 00 07 82 8C 8C 82 82 00 00
					39 00 00 40 00 00 07 83 82 78 78 6E 00 00
					39 00 00 40 00 00 07 84 6E 64 64 64 00 00
					39 00 00 40 00 00 07 85 5A 5A 5B 5B 00 00
					39 00 00 40 00 00 07 86 5C 5C 5C 5C 00 00
					39 00 00 40 00 00 07 87 4D 4D 00 00 11 00
					39 00 00 40 00 00 04 FF 5A A5 53
					39 00 00 40 00 00 03 85 CC E3
					39 00 00 40 00 00 04 FF 5A A5 00
					15 00 00 40 00 00 02 60 03 //DC 90hz
					39 00 00 40 00 00 04 FF 5A A5 2D
					39 00 00 40 00 00 03 86 00 00
					15 00 00 40 00 00 02 F2 00
					39 00 00 00 00 00 04 FF 5A A5 00
				];
				qcom,mdss-dsi-timming-switch-pwm-mode2-command = [
					39 00 00 40 00 00 04 FF 5A A5 53
					39 00 00 40 00 00 03 85 CC E3
					39 00 00 40 00 00 04 FF 5A A5 00
					15 00 00 40 00 00 02 60 03 //DC 90Hz
					39 00 00 40 00 00 04 FF 5A A5 2D
					39 00 00 40 00 00 03 86 00 00
					15 00 00 40 00 00 02 F2 00
					39 00 00 00 00 00 04 FF 5A A5 00
				];
				qcom,mdss-dsi-pwm-switch-mode2-panel-on-command = [
					39 00 00 40 00 00 04 FF 5A A5 51
					39 00 00 40 00 00 07 A0 AF AF AF AF 22 22
					39 00 00 40 00 00 07 A1 AF AF AF AF 22 22
					39 00 00 40 00 00 07 A2 AF AF AF AF 22 22
					39 00 00 40 00 00 07 A3 AF AF AF AF 22 22
					39 00 00 40 00 00 07 A4 AF AF AF AF 22 22
					39 00 00 40 00 00 07 A5 AF AF BC BC 22 22
					39 00 00 40 00 00 07 A6 C0 C0 C0 C0 22 22
					39 00 00 40 00 00 07 A7 CA CA 00 00 22 00
					39 00 00 40 00 00 04 FF 5A A5 52
					39 00 00 40 00 00 07 80 5E 2C B4 AA 11 00
					39 00 00 40 00 00 07 81 A0 A0 96 96 00 00
					39 00 00 40 00 00 07 82 8C 8C 82 82 00 00
					39 00 00 40 00 00 07 83 82 78 78 6E 00 00
					39 00 00 40 00 00 07 84 6E 64 64 64 00 00
					39 00 00 40 00 00 07 85 5A 5A 5B 5B 00 00
					39 00 00 40 00 00 07 86 5C 5C 5C 5C 00 00
					39 00 00 40 00 00 07 87 4D 4D 00 00 11 00
					39 00 00 40 00 00 04 FF 5A A5 53
					39 00 00 40 00 00 03 85 CC E3
					39 00 00 40 00 00 04 FF 5A A5 00
					15 00 00 40 00 00 02 60 03 //DC 90hz
					39 00 00 40 00 00 04 FF 5A A5 2D
					39 00 00 40 00 00 03 86 00 00
					15 00 00 40 00 00 02 F2 00
					39 00 00 00 00 00 04 FF 5A A5 00
				];
				qcom,mdss-dsi-lhbm-pressed-icon-on-command = [
					39 00 00 40 00 00 04 FF 5A A5 00
					15 00 00 40 00 00 02 96 09
					15 00 00 40 00 00 02 97 5B
					39 00 00 00 00 00 02 6E 03
				];
				qcom,mdss-dsi-lhbm-pressed-icon-off-command = [
					39 00 00 40 00 00 04 FF 5A A5 00
					39 00 00 00 00 00 02 6E 00
				];
				qcom,mdss-dsi-lp1-command = [
					39 00 00 40 00 00 04 FF 5A A5 00
					15 00 00 40 00 00 01 39
					39 00 00 40 00 00 04 FF 5A A5 2D
					15 00 00 40 00 00 03 8A 00 00
					/* AOD lv switch */
					39 00 00 40 00 00 04 FF 5A A5 00
					39 00 00 00 00 00 05 51 0D BB 0D BB
				];
				qcom,mdss-dsi-nolp-command = [
					39 00 00 40 00 00 04 FF 5A A5 00
					15 00 00 40 00 00 01 38
					39 00 00 00 00 00 05 51 00 00 00 00
				];
				qcom,mdss-dsi-aod-off-pwm-mode2-command = [
				];
				qcom,mdss-dsi-aod-off-compensation-command = [
				];
				qcom,mdss-dsi-aod-off-compensation-onepulse-command = [
				];
				qcom,mdss-dsi-aod-high-mode-command = [
					39 00 00 40 00 00 04 FF 5A A5 00
					39 00 00 00 00 00 05 51 0D BB 0D BB
				];
				qcom,mdss-dsi-aod-low-mode-command = [
					39 00 00 40 00 00 04 FF 5A A5 00
					39 00 00 00 00 00 05 51 0D BB 00 03
				];
				qcom,mdss-dsi-ultra-low-power-aod-on-command = [
					39 00 00 40 00 00 04 FF 5A A5 2D
					39 00 00 40 00 00 03 8A 02 00
					39 00 00 00 00 00 04 FF 5A A5 00
				];
				qcom,mdss-dsi-ultra-low-power-aod-off-command = [
					39 00 00 40 00 00 04 FF 5A A5 2D
					39 00 00 40 00 00 03 8A 00 00
					39 00 00 00 00 00 04 FF 5A A5 00
				];
				qcom,mdss-dsi-hbm-max-command = [
					39 00 00 00 00 00 03 51 10 ED
				];
				qcom,mdss-dsi-hbm-exit-max-command = [
					39 00 00 00 00 00 03 51 0F FE
				];
				qcom,mdss-dsi-lp1-command-state = "dsi_hs_mode";
				qcom,mdss-dsi-nolp-command-state = "dsi_hs_mode";
				qcom,mdss-dsi-aod-off-pwm-mode2-command-state = "dsi_hs_mode";
				qcom,mdss-dsi-aod-off-compensation-command-state = "dsi_lp_mode";
				qcom,mdss-dsi-aod-off-compensation-onepulse-command-state = "dsi_lp_mode";
				qcom,mdss-dsi-nolp-hpwm-command-state = "dsi_lp_mode";
				qcom,mdss-dsi-hbm-on-command-state = "dsi_hs_mode";
				qcom,mdss-dsi-hbm-off-command-state = "dsi_hs_mode";
				qcom,mdss-dsi-panel-read-register-open-state = "dsi_lp_mode";
				qcom,mdss-dsi-panel-read-register-close-state = "dsi_lp_mode";
				qcom,mdss-dsi-lhbm-pressed-icon-gamma-command-state = "dsi_lp_mode";
				qcom,mdss-dsi-lhbm-pressed-icon-grayscale-command-state = "dsi_lp_mode";
				qcom,mdss-dsi-lhbm-pressed-icon-on-command-state = "dsi_lp_mode";
				qcom,mdss-dsi-lhbm-pressed-icon-off-command-state = "dsi_lp_mode";
				qcom,mdss-dsi-lhbm-dbv-alpha-command-state = "dsi_hs_mode";

				qcom,mdss-dsi-reset-scanline-command-state = "dsi_hs_mode";
				qcom,mdss-dsi-recovery-scanline-command-state = "dsi_hs_mode";

				qcom,mdss-dsi-osc-track-on-command-state = "dsi_hs_mode";
				qcom,mdss-dsi-osc-track-off-command-state = "dsi_hs_mode";
				qcom,mdss-dsi-hbm-max-command-state = "dsi_hs_mode";
				qcom,mdss-dsi-hbm-exit-max-command-state = "dsi_hs_mode";

				qcom,lm-split = <608 608>;
				qcom,compression-mode = "dsc";
				qcom,mdss-dsc-encoders = <2>;
				qcom,mdss-dsc-slice-height = <20>;
				qcom,mdss-dsc-slice-width = <608>;
				qcom,mdss-dsc-slice-per-pkt = <2>;
				qcom,mdss-dsc-bit-per-component = <10>;
				qcom,mdss-dsc-bit-per-pixel = <8>;
				qcom,mdss-dsc-block-prediction-enable;
			};
			timing@sa_fhd_60 {
				#include "dsi-panel-AA594-P-7-A0020-common.dtsi"
				#include "dsi-panel-AA594-P-7-A0020-common-effect.dtsi"
				cell-index = <2>;
				qcom,mdss-mdp-transfer-time-us = <6800>;
				qcom,mdss-dsi-panel-jitter = <0x4 0x1>;
				qcom,mdss-dsc-version = <0x12>;
				qcom,mdss-dsi-timing-default;
				qcom,mdss-dsi-panel-framerate = <60>;
				qcom,mdss-dsi-panel-clockrate = <1096000000>;
				qcom,mdss-dsi-panel-width = <1216>;
				qcom,mdss-dsi-panel-height = <2640>;

				qcom,mdss-dsi-h-front-porch = <16>;
				qcom,mdss-dsi-h-back-porch = <16>;
				qcom,mdss-dsi-h-pulse-width = <2>;
				qcom,mdss-dsi-v-back-porch = <36>;
				qcom,mdss-dsi-v-front-porch = <60>;
				qcom,mdss-dsi-v-pulse-width = <4>;
				qcom,mdss-dsi-h-sync-pulse = <0>;

				oplus,ofp-backlight-on-period = <1>;
				oplus,apollo-panel-async-bl-delay = <9000>;

				/* Apollo vsync config, need to measure TE signal */
				oplus,apollo-panel-vsync-width = <8600>;

				qcom,mdss-dsi-timing-switch-command = [
					/* Switch To 60Hz (Normal 1+18 pulse) */
					39 00 00 40 00 00 04 FF 5A A5 53
					39 00 00 40 00 00 03 85 CC E1
					39 00 00 40 00 00 04 FF 5A A5 00
					15 00 00 40 00 00 02 60 00 //60hz
					39 00 00 40 00 00 04 FF 5A A5 2D
					39 00 00 40 00 00 03 83 01 00
					15 00 00 40 00 00 02 F2 01
					39 00 00 00 00 00 04 FF 5A A5 00
				];
				qcom,mdss-dsi-on-command = [
					/* DSC setting */
					39 00 00 40 00 00 04 FF 5A A5 1F
					39 00 00 40 00 00 04 83 2C 00 4E
					39 00 00 40 00 00 04 84 1B 00 4E
					39 00 00 00 00 00 04 85 35 00 4E
					39 00 00 40 00 00 04 FF 5A A5 07
					15 00 00 40 00 00 02 8A 01
					39 00 00 40 00 00 03 8B 21 A0
					39 00 00 40 00 00 64 80 00 00 00 00 00
							12 00 00 AB 21 00 0A 50 04 C0 00 14
							02 60 02 60 01 55 01 D3 00 0A 01 08
							00 33 00 0D 05 7A 19 5A 08 00 0B F0
							07 10 20 00 06 0F 0F 33 0E 1C 2A 38
							46 54 62 69 70 77 79 7B 7D 7E 00 82
							11 40 19 C0 22 3E 32 7C 3A BA 3A F8
							3B 38 3B 38 3B 76 4B 76 4B 74 4B 74
							5B B4 73 F4 01 00 00 00 00 00
					15 00 00 40 00 00 02 91 03
					39 00 00 40 00 00 04 FF 5A A5 14
					15 00 00 40 00 00 02 80 00
					15 00 00 40 00 00 02 82 01
					39 00 00 00 00 00 04 FF 5A A5 00
					/* Common setting */
					39 00 00 40 00 00 04 FF 5A A5 08
					15 00 00 40 00 00 02 C8 62
					39 00 00 40 00 00 04 FF 5A A5 21
					15 00 00 40 00 00 02 A4 18
					39 00 00 40 00 00 04 FF 5A A5 00
					15 00 00 40 00 00 02 5E 01
					15 00 00 40 00 00 02 60 00
					15 00 00 40 00 00 02 61 07
					15 00 00 40 00 00 02 6D 01
					05 00 00 40 00 00 01 35
					15 00 00 40 00 00 02 53 20
					39 00 00 40 00 00 04 FF 5A A5 06
					15 00 00 40 00 00 02 C6 01 //1bit ESD Check
					39 00 00 40 00 00 04 FF 5A A5 08
					15 00 00 40 00 00 02 D2 05
					15 00 00 40 00 00 02 D3 01
					39 00 00 40 00 00 0A ED FF FF FF 0F 07 FF CF 45 FF //Golden CRC
					39 00 00 40 00 00 09 EE FF FD C1 F8 21 00 80 50
					39 00 00 40 00 00 04 FF 5A A5 20
					15 00 00 40 00 00 02 BC 07 //GPO1 TEST TE
					15 00 00 40 00 00 02 BD 06 //GPO0 SYNC TE
					39 00 00 00 00 00 04 FF 5A A5 00
					/* Corner/Hole/Edge OFF */
					39 00 00 40 00 00 04 FF 5A A5 17
					15 00 00 40 00 00 02 A0 0C
					39 00 00 00 00 00 04 FF 5A A5 00
					/* Switch To 60Hz (Normal 1+18 pulse) */
					39 00 00 40 00 00 04 FF 5A A5 53
					39 00 00 40 00 00 03 85 CC E1
					39 00 00 40 00 00 04 FF 5A A5 00
					15 00 00 40 00 00 02 60 00 //60hz
					39 00 00 40 00 00 04 FF 5A A5 2D
					39 00 00 40 00 00 03 83 01 00
					15 00 00 40 00 00 02 F2 01
					39 00 00 00 00 00 04 FF 5A A5 00
					39 00 00 40 00 00 04 FF 5A A5 1E
					15 00 00 40 00 00 02 9B 02
					39 00 00 00 00 00 04 FF 5A A5 00
					05 00 00 00 78 00 01 11
					05 00 00 00 00 00 01 29
				];
				qcom,mdss-dsi-optimize-on-command = [
					/* DSC setting */
					39 00 00 40 00 00 04 FF 5A A5 07
					15 00 00 40 00 00 02 8A 01
					39 00 00 40 00 00 03 8B 21 A0
					39 00 00 40 00 00 64 80 00 00 00 00 00
							12 00 00 AB 21 00 0A 50 04 C0 00 14
							02 60 02 60 01 55 01 D3 00 0A 01 08
							00 33 00 0D 05 7A 19 5A 08 00 0B F0
							07 10 20 00 06 0F 0F 33 0E 1C 2A 38
							46 54 62 69 70 77 79 7B 7D 7E 00 82
							11 40 19 C0 22 3E 32 7C 3A BA 3A F8
							3B 38 3B 38 3B 76 4B 76 4B 74 4B 74
							5B B4 73 F4 01 00 00 00 00 00
					15 00 00 40 00 00 02 91 03
					39 00 00 40 00 00 04 FF 5A A5 14
					15 00 00 40 00 00 02 80 00
					15 00 00 40 00 00 02 82 01
					39 00 00 00 00 00 04 FF 5A A5 00
					/* Common setting */
					39 00 00 40 00 00 04 FF 5A A5 08
					15 00 00 40 00 00 02 C8 62
					39 00 00 40 00 00 04 FF 5A A5 21
					15 00 00 40 00 00 02 A4 18
					39 00 00 40 00 00 04 FF 5A A5 00
					15 00 00 40 00 00 02 5E 01
					15 00 00 40 00 00 02 60 00
					15 00 00 40 00 00 02 61 07
					15 00 00 40 00 00 02 6D 01
					05 00 00 40 00 00 01 35
					15 00 00 40 00 00 02 53 20
					39 00 00 40 00 00 04 FF 5A A5 06
					15 00 00 40 00 00 02 C6 01 //1bit ESD Check
					39 00 00 40 00 00 04 FF 5A A5 08
					15 00 00 40 00 00 02 D2 05
					15 00 00 40 00 00 02 D3 01
					39 00 00 40 00 00 0A ED FF FF FF 0F 07 FF CF 45 FF //Golden CRC
					39 00 00 40 00 00 09 EE FF FD C1 F8 21 00 80 50
					39 00 00 40 00 00 04 FF 5A A5 20
					15 00 00 40 00 00 02 BC 07 //GPO1 TEST TE
					15 00 00 40 00 00 02 BD 06 //GPO0 SYNC TE
					39 00 00 00 00 00 04 FF 5A A5 00
					/* Corner/Hole/Edge OFF */
					39 00 00 40 00 00 04 FF 5A A5 17
					15 00 00 40 00 00 02 A0 0C
					39 00 00 00 00 00 04 FF 5A A5 00
					/* Switch To 60 Hz (Normal 1+18 pulse) */
					39 00 00 40 00 00 04 FF 5A A5 4E
					39 00 00 40 00 00 5B CF 00 14 14 14 14 14 08 88 88 00 00 00 00 00 00 00 00 00 00 08 08 08 08 08 08 88 88 00 00 00 00 00 00 00 00 00 00 08 08 08 08 08 08 88 88 00 00 00 00 00 00 00 00 00 00 00 00 00 00 00 08 88 88 00 00 00 00 00 00 00 00 00 00 00 00 00 00 00 08 88 88 00 00 00 00 00 00 00 00 00
					39 00 00 40 00 00 5B D0 00 0F 0F 0F 0F 0F 08 88 88 00 00 00 00 00 00 00 00 00 00 0B 0B 0B 0B 0B 08 88 88 00 00 00 00 00 00 00 00 00 00 0B 0B 0B 0B 0B 08 88 88 00 00 00 00 00 00 00 00 00 00 07 07 07 07 07 08 88 88 00 00 00 00 00 00 00 00 00 00 07 07 07 07 07 08 88 88 00 00 00 00 00 00 00 00 00
					39 00 00 40 00 00 04 FF 5A A5 53
					39 00 00 40 00 00 03 85 CC E1
					39 00 00 40 00 00 04 FF 5A A5 00
					15 00 00 40 00 00 02 60 00 //60Hz
					39 00 00 40 00 00 04 FF 5A A5 2D
					39 00 00 40 00 00 03 83 01 00
					15 00 00 40 00 00 02 F2 01
					39 00 00 00 00 00 04 FF 5A A5 00
					39 00 00 40 00 00 04 FF 5A A5 1E
					39 00 00 40 00 00 04 C1 10 9C C9
					39 00 00 40 00 00 08 C2 FF FF FF 60 60 63 63
					39 00 00 40 00 00 04 FF 5A A5 1F
					39 00 00 40 00 00 07 C1 00 00 00 00 1F FF
					39 00 00 00 00 00 1F C2 AB D7 D8 E2 1F FF 25 27 FF FF FF FF FF FF FF FF FF FF FF FF FF FF FF FF FF FF FF FF FF FF
					05 00 00 00 78 00 01 11
					05 00 00 00 00 00 01 29
				];
				qcom,mdss-dsi-off-command=[
					05 00 00 00 14 00 01 28
					05 00 00 00 78 00 01 10
				];
				qcom,mdss-dsi-hbm-off-command = [
					39 00 00 00 00 00 03 51 0D BB
				];
				qcom,mdss-dsi-hbm-on-command = [
					39 00 00 00 00 00 03 51 0E E0
				];
				/* pwm */
				qcom,mdss-dsi-pwm-switch-mode1-command= [
					39 00 00 40 00 00 04 FF 5A A5 51
					39 00 00 40 00 00 07 A0 AF AF AF AF 22 22
					39 00 00 40 00 00 07 A1 AF AF AF AF 22 22
					39 00 00 40 00 00 07 A2 AF AF AF AF 22 22
					39 00 00 40 00 00 07 A3 AF AF AF AF 22 22
					39 00 00 40 00 00 07 A4 AF AF AF AF 22 22
					39 00 00 40 00 00 07 A5 AF AF B9 B9 22 22
					39 00 00 40 00 00 07 A6 B3 B3 B6 B6 22 22
					39 00 00 40 00 00 07 A7 D4 D4 00 00 22 00
					39 00 00 40 00 00 04 FF 5A A5 52
					39 00 00 40 00 00 07 80 5E 2C B4 AA 11 00
					39 00 00 40 00 00 07 81 A0 A0 96 96 00 00
					39 00 00 40 00 00 07 82 8C 8C 82 82 00 00
					39 00 00 40 00 00 07 83 82 78 78 6E 00 00
					39 00 00 40 00 00 07 84 6E 64 64 64 00 00
					39 00 00 40 00 00 07 85 5A 5A 5C 5C 00 00
					39 00 00 40 00 00 07 86 5D 5D 5D 5D 00 00
					39 00 00 40 00 00 07 87 52 52 00 00 11 00
					39 00 00 40 00 00 04 FF 5A A5 53
					39 00 00 40 00 00 03 85 CC E1
					39 00 00 40 00 00 04 FF 5A A5 00
					15 00 00 40 00 00 02 60 00 //60hz
					39 00 00 40 00 00 04 FF 5A A5 2D
					39 00 00 40 00 00 03 83 01 00
					15 00 00 40 00 00 02 F2 01
					39 00 00 00 00 00 04 FF 5A A5 00
				];
				qcom,mdss-dsi-pwm-switch-mode2-command = [
					39 00 00 40 00 00 04 FF 5A A5 51
					39 00 00 40 00 00 07 A0 AF AF AF AF 22 22
					39 00 00 40 00 00 07 A1 AF AF AF AF 22 22
					39 00 00 40 00 00 07 A2 AF AF AF AF 22 22
					39 00 00 40 00 00 07 A3 AF AF AF AF 22 22
					39 00 00 40 00 00 07 A4 AF AF AF AF 22 22
					39 00 00 40 00 00 07 A5 AF AF BC BC 22 22
					39 00 00 40 00 00 07 A6 C0 C0 C0 C0 22 22
					39 00 00 40 00 00 07 A7 CA CA 00 00 22 00
					39 00 00 40 00 00 04 FF 5A A5 52
					39 00 00 40 00 00 07 80 5E 2C B4 AA 11 00
					39 00 00 40 00 00 07 81 A0 A0 96 96 00 00
					39 00 00 40 00 00 07 82 8C 8C 82 82 00 00
					39 00 00 40 00 00 07 83 82 78 78 6E 00 00
					39 00 00 40 00 00 07 84 6E 64 64 64 00 00
					39 00 00 40 00 00 07 85 5A 5A 5B 5B 00 00
					39 00 00 40 00 00 07 86 5C 5C 5C 5C 00 00
					39 00 00 40 00 00 07 87 4D 4D 00 00 11 00
					39 00 00 40 00 00 04 FF 5A A5 53
					39 00 00 40 00 00 03 85 CC E3
					39 00 00 40 00 00 04 FF 5A A5 53
					39 00 00 40 00 00 03 85 CC E3
					39 00 00 40 00 00 04 FF 5A A5 00
					15 00 00 40 00 00 02 60 01 //DC 60hz
					39 00 00 40 00 00 04 FF 5A A5 2D
					39 00 00 40 00 00 03 84 01 00
					15 00 00 40 00 00 02 F2 01
					39 00 00 00 00 00 04 FF 5A A5 00
				];
				qcom,mdss-dsi-timming-switch-pwm-mode2-command = [
					39 00 00 40 00 00 04 FF 5A A5 53
					39 00 00 40 00 00 03 85 CC E3
					39 00 00 40 00 00 04 FF 5A A5 00
					15 00 00 40 00 00 02 60 01 //DC 60Hz
					39 00 00 40 00 00 04 FF 5A A5 2D
					39 00 00 40 00 00 03 84 01 00
					15 00 00 40 00 00 02 F2 01
					39 00 00 00 00 00 04 FF 5A A5 00
				];
				qcom,mdss-dsi-pwm-switch-mode2-panel-on-command = [
					39 00 00 40 00 00 04 FF 5A A5 51
					39 00 00 40 00 00 07 A0 AF AF AF AF 22 22
					39 00 00 40 00 00 07 A1 AF AF AF AF 22 22
					39 00 00 40 00 00 07 A2 AF AF AF AF 22 22
					39 00 00 40 00 00 07 A3 AF AF AF AF 22 22
					39 00 00 40 00 00 07 A4 AF AF AF AF 22 22
					39 00 00 40 00 00 07 A5 AF AF BC BC 22 22
					39 00 00 40 00 00 07 A6 C0 C0 C0 C0 22 22
					39 00 00 40 00 00 07 A7 CA CA 00 00 22 00
					39 00 00 40 00 00 04 FF 5A A5 52
					39 00 00 40 00 00 07 80 5E 2C B4 AA 11 00
					39 00 00 40 00 00 07 81 A0 A0 96 96 00 00
					39 00 00 40 00 00 07 82 8C 8C 82 82 00 00
					39 00 00 40 00 00 07 83 82 78 78 6E 00 00
					39 00 00 40 00 00 07 84 6E 64 64 64 00 00
					39 00 00 40 00 00 07 85 5A 5A 5B 5B 00 00
					39 00 00 40 00 00 07 86 5C 5C 5C 5C 00 00
					39 00 00 40 00 00 07 87 4D 4D 00 00 11 00
					39 00 00 40 00 00 04 FF 5A A5 53
					39 00 00 40 00 00 03 85 CC E3
					39 00 00 40 00 00 04 FF 5A A5 53
					39 00 00 40 00 00 03 85 CC E3
					39 00 00 40 00 00 04 FF 5A A5 00
					15 00 00 40 00 00 02 60 01 //DC 60hz
					39 00 00 40 00 00 04 FF 5A A5 2D
					39 00 00 40 00 00 03 84 01 00
					15 00 00 40 00 00 02 F2 01
					39 00 00 00 00 00 04 FF 5A A5 00
				];
				qcom,mdss-dsi-lhbm-pressed-icon-on-command = [
					39 00 00 40 00 00 04 FF 5A A5 00
					15 00 00 40 00 00 02 96 09
					15 00 00 40 00 00 02 97 5B
					39 00 00 00 00 00 02 6E 03
				];
				qcom,mdss-dsi-lhbm-pressed-icon-off-command = [
					39 00 00 40 00 00 04 FF 5A A5 00
					39 00 00 00 00 00 02 6E 00
				];
				qcom,mdss-dsi-lp1-command = [
					39 00 00 40 00 00 04 FF 5A A5 00
					15 00 00 40 00 00 01 39
					39 00 00 40 00 00 04 FF 5A A5 2D
					15 00 00 40 00 00 03 8A 00 00
					/* AOD lv switch */
					39 00 00 40 00 00 04 FF 5A A5 00
					39 00 00 00 00 00 05 51 0D BB 0D BB
				];
				qcom,mdss-dsi-nolp-command = [
					39 00 00 40 00 00 04 FF 5A A5 00
					15 00 00 40 00 00 01 38
					39 00 00 00 00 00 05 51 00 00 00 00
				];
				qcom,mdss-dsi-aod-off-pwm-mode2-command = [
				];
				qcom,mdss-dsi-aod-off-compensation-command = [
				];
				qcom,mdss-dsi-aod-off-compensation-onepulse-command = [
				];
				qcom,mdss-dsi-aod-high-mode-command = [
					39 00 00 40 00 00 04 FF 5A A5 00
					39 00 00 00 00 00 05 51 0D BB 0D BB
				];
				qcom,mdss-dsi-aod-low-mode-command = [
					39 00 00 40 00 00 04 FF 5A A5 00
					39 00 00 00 00 00 05 51 0D BB 00 03
				];
				qcom,mdss-dsi-ultra-low-power-aod-on-command = [
					39 00 00 40 00 00 04 FF 5A A5 2D
					39 00 00 40 00 00 03 8A 02 00
					39 00 00 00 00 00 04 FF 5A A5 00
				];
				qcom,mdss-dsi-ultra-low-power-aod-off-command = [
					39 00 00 40 00 00 04 FF 5A A5 2D
					39 00 00 40 00 00 03 8A 00 00
					39 00 00 00 00 00 04 FF 5A A5 00
				];
				qcom,mdss-dsi-hbm-max-command = [
					39 00 00 00 00 00 03 51 10 ED
				];
				qcom,mdss-dsi-hbm-exit-max-command = [
					39 00 00 00 00 00 03 51 0F FE
				];
				qcom,mdss-dsi-lp1-command-state = "dsi_hs_mode";
				qcom,mdss-dsi-nolp-command-state = "dsi_hs_mode";
				qcom,mdss-dsi-aod-off-pwm-mode2-command-state = "dsi_hs_mode";
				qcom,mdss-dsi-aod-off-compensation-command-state = "dsi_lp_mode";
				qcom,mdss-dsi-aod-off-compensation-onepulse-command-state = "dsi_lp_mode";
				qcom,mdss-dsi-nolp-hpwm-command-state = "dsi_lp_mode";
				qcom,mdss-dsi-hbm-on-command-state = "dsi_hs_mode";
				qcom,mdss-dsi-hbm-off-command-state = "dsi_hs_mode";
				qcom,mdss-dsi-panel-read-register-open-state = "dsi_lp_mode";
				qcom,mdss-dsi-panel-read-register-close-state = "dsi_lp_mode";
				qcom,mdss-dsi-lhbm-pressed-icon-gamma-command-state = "dsi_lp_mode";
				qcom,mdss-dsi-lhbm-pressed-icon-grayscale-command-state = "dsi_lp_mode";
				qcom,mdss-dsi-lhbm-pressed-icon-on-command-state = "dsi_lp_mode";
				qcom,mdss-dsi-lhbm-pressed-icon-off-command-state = "dsi_lp_mode";
				qcom,mdss-dsi-lhbm-dbv-alpha-command-state = "dsi_hs_mode";

				qcom,mdss-dsi-reset-scanline-command-state = "dsi_hs_mode";
				qcom,mdss-dsi-recovery-scanline-command-state = "dsi_hs_mode";

				qcom,mdss-dsi-osc-track-on-command-state = "dsi_hs_mode";
				qcom,mdss-dsi-osc-track-off-command-state = "dsi_hs_mode";
				qcom,mdss-dsi-hbm-max-command-state = "dsi_hs_mode";
				qcom,mdss-dsi-hbm-exit-max-command-state = "dsi_hs_mode";

				qcom,lm-split = <608 608>;
				qcom,compression-mode = "dsc";
				qcom,mdss-dsc-encoders = <2>;
				qcom,mdss-dsc-slice-height = <20>;
				qcom,mdss-dsc-slice-width = <608>;
				qcom,mdss-dsc-slice-per-pkt = <2>;
				qcom,mdss-dsc-bit-per-component = <10>;
				qcom,mdss-dsc-bit-per-pixel = <8>;
				qcom,mdss-dsc-block-prediction-enable;
			};
			timing@oa_fhd_120 {
				#include "dsi-panel-AA594-P-7-A0020-common.dtsi"
				#include "dsi-panel-AA594-P-7-A0020-common-effect.dtsi"
				cell-index = <3>;
				qcom,mdss-mdp-transfer-time-us = <6800>;
				qcom,mdss-dsi-panel-jitter = <0x4 0x1>;
				qcom,mdss-dsc-version = <0x12>;
				qcom,mdss-dsi-timing-default;
				qcom,mdss-dsi-panel-framerate = <120>;
				qcom,mdss-dsi-panel-clockrate = <1096000000>;
				qcom,mdss-dsi-panel-width = <1216>;
				qcom,mdss-dsi-panel-height = <2640>;

				qcom,mdss-dsi-h-front-porch = <16>;
				qcom,mdss-dsi-h-back-porch = <16>;
				qcom,mdss-dsi-h-pulse-width = <2>;
				qcom,mdss-dsi-v-back-porch = <36>;
				qcom,mdss-dsi-v-front-porch = <60>;
				qcom,mdss-dsi-v-pulse-width = <4>;
				qcom,mdss-dsi-h-sync-pulse = <0>;

				oplus,ofp-backlight-on-period = <1>;

				qcom,mdss-dsi-timing-switch-command = [
					/* Switch To 120Hz(Normal 1+18 pulse) */
					39 00 00 40 00 00 04 FF 5A A5 53
					39 00 00 40 00 00 03 85 CC E1
					39 00 00 40 00 00 04 FF 5A A5 00
					15 00 00 40 00 00 02 60 00 //120hz
					39 00 00 40 00 00 04 FF 5A A5 2D
					39 00 00 40 00 00 03 83 00 00
					15 00 00 40 00 00 02 F2 00
					39 00 00 00 00 00 04 FF 5A A5 00
				];
				qcom,mdss-dsi-on-command = [
					/* DSC setting */
					39 00 00 40 00 00 04 FF 5A A5 1F
					39 00 00 40 00 00 04 83 2C 00 4E
					39 00 00 40 00 00 04 84 1B 00 4E
					39 00 00 00 00 00 04 85 35 00 4E
					39 00 00 40 00 00 04 FF 5A A5 07
					15 00 00 40 00 00 02 8A 01
					39 00 00 40 00 00 03 8B 21 A0
					39 00 00 40 00 00 64 80 00 00 00 00 00
							12 00 00 AB 21 00 0A 50 04 C0 00 14
							02 60 02 60 01 55 01 D3 00 0A 01 08
							00 33 00 0D 05 7A 19 5A 08 00 0B F0
							07 10 20 00 06 0F 0F 33 0E 1C 2A 38
							46 54 62 69 70 77 79 7B 7D 7E 00 82
							11 40 19 C0 22 3E 32 7C 3A BA 3A F8
							3B 38 3B 38 3B 76 4B 76 4B 74 4B 74
							5B B4 73 F4 01 00 00 00 00 00
					15 00 00 40 00 00 02 91 03
					39 00 00 40 00 00 04 FF 5A A5 14
					15 00 00 40 00 00 02 80 00
					15 00 00 40 00 00 02 82 01
					39 00 00 00 00 00 04 FF 5A A5 00
					/* Common setting */
					39 00 00 40 00 00 04 FF 5A A5 08
					15 00 00 40 00 00 02 C8 62
					39 00 00 40 00 00 04 FF 5A A5 21
					15 00 00 40 00 00 02 A4 18
					39 00 00 40 00 00 04 FF 5A A5 00
					15 00 00 40 00 00 02 5E 01
					15 00 00 40 00 00 02 60 00
					15 00 00 40 00 00 02 61 07
					15 00 00 40 00 00 02 6D 01
					05 00 00 40 00 00 01 35
					15 00 00 40 00 00 02 53 20
					39 00 00 40 00 00 04 FF 5A A5 06
					15 00 00 40 00 00 02 C6 01 //1bit ESD Check
					39 00 00 40 00 00 04 FF 5A A5 08
					15 00 00 40 00 00 02 D2 05
					15 00 00 40 00 00 02 D3 01
					39 00 00 40 00 00 0A ED FF FF FF 0F 07 FF CF 45 FF //Golden CRC
					39 00 00 40 00 00 09 EE FF FD C1 F8 21 00 80 50
					39 00 00 40 00 00 04 FF 5A A5 20
					15 00 00 40 00 00 02 BC 07 //GPO1 TEST TE
					15 00 00 40 00 00 02 BD 06 //GPO0 SYNC TE
					39 00 00 00 00 00 04 FF 5A A5 00
					/* Corner/Hole/Edge OFF */
					39 00 00 40 00 00 04 FF 5A A5 17
					15 00 00 40 00 00 02 A0 0C
					39 00 00 00 00 00 04 FF 5A A5 00
					/* Switch To 120Hz(Normal 1+18 pulse) */
					39 00 00 40 00 00 04 FF 5A A5 53
					39 00 00 40 00 00 03 85 CC E1
					39 00 00 40 00 00 04 FF 5A A5 00
					15 00 00 40 00 00 02 60 00 //120hz
					39 00 00 40 00 00 04 FF 5A A5 2D
					39 00 00 40 00 00 03 83 00 00
					15 00 00 40 00 00 02 F2 00
					39 00 00 00 00 00 04 FF 5A A5 00
					39 00 00 40 00 00 04 FF 5A A5 1E
					15 00 00 40 00 00 02 9B 02
					39 00 00 00 00 00 04 FF 5A A5 00
					05 00 00 00 78 00 01 11
					05 00 00 00 00 00 01 29
				];
				qcom,mdss-dsi-optimize-on-command = [
					/* DSC setting */
					39 00 00 40 00 00 04 FF 5A A5 07
					15 00 00 40 00 00 02 8A 01
					39 00 00 40 00 00 03 8B 21 A0
					39 00 00 40 00 00 64 80 00 00 00 00 00
							12 00 00 AB 21 00 0A 50 04 C0 00 14
							02 60 02 60 01 55 01 D3 00 0A 01 08
							00 33 00 0D 05 7A 19 5A 08 00 0B F0
							07 10 20 00 06 0F 0F 33 0E 1C 2A 38
							46 54 62 69 70 77 79 7B 7D 7E 00 82
							11 40 19 C0 22 3E 32 7C 3A BA 3A F8
							3B 38 3B 38 3B 76 4B 76 4B 74 4B 74
							5B B4 73 F4 01 00 00 00 00 00
					15 00 00 40 00 00 02 91 03
					39 00 00 40 00 00 04 FF 5A A5 14
					15 00 00 40 00 00 02 80 00
					15 00 00 40 00 00 02 82 01
					39 00 00 00 00 00 04 FF 5A A5 00
					/* Common setting */
					39 00 00 40 00 00 04 FF 5A A5 08
					15 00 00 40 00 00 02 C8 62
					39 00 00 40 00 00 04 FF 5A A5 21
					15 00 00 40 00 00 02 A4 18
					39 00 00 40 00 00 04 FF 5A A5 00
					15 00 00 40 00 00 02 5E 01
					15 00 00 40 00 00 02 60 00
					15 00 00 40 00 00 02 61 07
					15 00 00 40 00 00 02 6D 01
					05 00 00 40 00 00 01 35
					15 00 00 40 00 00 02 53 20
					39 00 00 40 00 00 04 FF 5A A5 06
					15 00 00 40 00 00 02 C6 01 //1bit ESD Check
					39 00 00 40 00 00 04 FF 5A A5 08
					15 00 00 40 00 00 02 D2 05
					15 00 00 40 00 00 02 D3 01
					39 00 00 40 00 00 0A ED FF FF FF 0F 07 FF CF 45 FF //Golden CRC
					39 00 00 40 00 00 09 EE FF FD C1 F8 21 00 80 50
					39 00 00 40 00 00 04 FF 5A A5 20
					15 00 00 40 00 00 02 BC 07 //GPO1 TEST TE
					15 00 00 40 00 00 02 BD 06 //GPO0 SYNC TE
					39 00 00 00 00 00 04 FF 5A A5 00
					/* Corner/Hole/Edge OFF */
					39 00 00 40 00 00 04 FF 5A A5 17
					15 00 00 40 00 00 02 A0 0C
					39 00 00 00 00 00 04 FF 5A A5 00
					/* Switch To 120Hz(Normal 1+18 pulse) */
					39 00 00 40 00 00 04 FF 5A A5 4E
					39 00 00 40 00 00 5B CF 00 14 14 14 14 14 08 88 88 00 00 00 00 00 00 00 00 00 00 08 08 08 08 08 08 88 88 00 00 00 00 00 00 00 00 00 00 08 08 08 08 08 08 88 88 00 00 00 00 00 00 00 00 00 00 00 00 00 00 00 08 88 88 00 00 00 00 00 00 00 00 00 00 00 00 00 00 00 08 88 88 00 00 00 00 00 00 00 00 00
					39 00 00 40 00 00 5B D0 00 0F 0F 0F 0F 0F 08 88 88 00 00 00 00 00 00 00 00 00 00 0B 0B 0B 0B 0B 08 88 88 00 00 00 00 00 00 00 00 00 00 0B 0B 0B 0B 0B 08 88 88 00 00 00 00 00 00 00 00 00 00 07 07 07 07 07 08 88 88 00 00 00 00 00 00 00 00 00 00 07 07 07 07 07 08 88 88 00 00 00 00 00 00 00 00 00
					39 00 00 40 00 00 04 FF 5A A5 53
					39 00 00 40 00 00 03 85 CC E1
					39 00 00 40 00 00 04 FF 5A A5 00
					15 00 00 40 00 00 02 60 00 //120Hz
					39 00 00 40 00 00 04 FF 5A A5 2D
					39 00 00 40 00 00 03 83 00 00
					15 00 00 40 00 00 02 F2 00
					39 00 00 00 00 00 04 FF 5A A5 00
					39 00 00 40 00 00 04 FF 5A A5 1E
					39 00 00 40 00 00 04 C1 10 9C C9
					39 00 00 40 00 00 08 C2 FF FF FF 60 60 63 63
					39 00 00 40 00 00 04 FF 5A A5 1F
					39 00 00 40 00 00 07 C1 00 00 00 00 1F FF
					39 00 00 00 00 00 1F C2 AB D7 D8 E2 1F FF 25 27 FF FF FF FF FF FF FF FF FF FF FF FF FF FF FF FF FF FF FF FF FF FF
					05 00 00 00 78 00 01 11
					05 00 00 00 00 00 01 29
				];
				qcom,mdss-dsi-off-command=[
					05 00 00 00 14 00 01 28
					05 00 00 00 78 00 01 10
				];
				qcom,mdss-dsi-hbm-off-command = [
					39 00 00 00 00 00 03 51 0D BB
				];
				qcom,mdss-dsi-hbm-on-command = [
					39 00 00 00 00 00 03 51 0E E0
				];
				/* pwm */
				qcom,mdss-dsi-pwm-switch-mode1-command= [
					39 00 00 40 00 00 04 FF 5A A5 51
					39 00 00 40 00 00 07 A0 AF AF AF AF 22 22
					39 00 00 40 00 00 07 A1 AF AF AF AF 22 22
					39 00 00 40 00 00 07 A2 AF AF AF AF 22 22
					39 00 00 40 00 00 07 A3 AF AF AF AF 22 22
					39 00 00 40 00 00 07 A4 AF AF AF AF 22 22
					39 00 00 40 00 00 07 A5 AF AF B9 B9 22 22
					39 00 00 40 00 00 07 A6 B3 B3 B6 B6 22 22
					39 00 00 40 00 00 07 A7 D4 D4 00 00 22 00
					39 00 00 40 00 00 04 FF 5A A5 52
					39 00 00 40 00 00 07 80 5E 2C B4 AA 11 00
					39 00 00 40 00 00 07 81 A0 A0 96 96 00 00
					39 00 00 40 00 00 07 82 8C 8C 82 82 00 00
					39 00 00 40 00 00 07 83 82 78 78 6E 00 00
					39 00 00 40 00 00 07 84 6E 64 64 64 00 00
					39 00 00 40 00 00 07 85 5A 5A 5C 5C 00 00
					39 00 00 40 00 00 07 86 5D 5D 5D 5D 00 00
					39 00 00 40 00 00 07 87 52 52 00 00 11 00
					39 00 00 40 00 00 04 FF 5A A5 00
					15 00 00 40 00 00 02 60 00 //120hz
					39 00 00 40 00 00 04 FF 5A A5 2D
					39 00 00 40 00 00 03 83 00 00
					15 00 00 40 00 00 02 F2 00
					39 00 00 40 00 00 04 FF 5A A5 53
					39 00 00 40 00 00 03 85 CC E1
					39 00 00 00 00 00 04 FF 5A A5 00
				];
				qcom,mdss-dsi-pwm-switch-mode2-command = [
					39 00 00 40 00 00 04 FF 5A A5 51
					39 00 00 40 00 00 07 A0 AF AF AF AF 22 22
					39 00 00 40 00 00 07 A1 AF AF AF AF 22 22
					39 00 00 40 00 00 07 A2 AF AF AF AF 22 22
					39 00 00 40 00 00 07 A3 AF AF AF AF 22 22
					39 00 00 40 00 00 07 A4 AF AF AF AF 22 22
					39 00 00 40 00 00 07 A5 AF AF BC BC 22 22
					39 00 00 40 00 00 07 A6 C0 C0 C0 C0 22 22
					39 00 00 40 00 00 07 A7 CA CA 00 00 22 00
					39 00 00 40 00 00 04 FF 5A A5 52
					39 00 00 40 00 00 07 80 5E 2C B4 AA 11 00
					39 00 00 40 00 00 07 81 A0 A0 96 96 00 00
					39 00 00 40 00 00 07 82 8C 8C 82 82 00 00
					39 00 00 40 00 00 07 83 82 78 78 6E 00 00
					39 00 00 40 00 00 07 84 6E 64 64 64 00 00
					39 00 00 40 00 00 07 85 5A 5A 5B 5B 00 00
					39 00 00 40 00 00 07 86 5C 5C 5C 5C 00 00
					39 00 00 40 00 00 07 87 4D 4D 00 00 11 00
					39 00 00 40 00 00 04 FF 5A A5 53
					39 00 00 40 00 00 03 85 CC E3
					39 00 00 40 00 00 04 FF 5A A5 00
					15 00 00 40 00 00 02 60 01 //DC 120hz
					39 00 00 40 00 00 04 FF 5A A5 2D
					39 00 00 40 00 00 03 84 00 00
					15 00 00 40 00 00 02 F2 00
					39 00 00 00 00 00 04 FF 5A A5 00
				];
				qcom,mdss-dsi-timming-switch-pwm-mode2-command = [
					39 00 00 40 00 00 04 FF 5A A5 53
					39 00 00 40 00 00 03 85 CC E3
					39 00 00 40 00 00 04 FF 5A A5 00
					15 00 00 40 00 00 02 60 01 //DC 120Hz
					39 00 00 40 00 00 04 FF 5A A5 2D
					39 00 00 40 00 00 03 84 00 00
					15 00 00 40 00 00 02 F2 00
					39 00 00 00 00 00 04 FF 5A A5 00
				];
				qcom,mdss-dsi-pwm-switch-mode2-panel-on-command = [
					39 00 00 40 00 00 04 FF 5A A5 51
					39 00 00 40 00 00 07 A0 AF AF AF AF 22 22
					39 00 00 40 00 00 07 A1 AF AF AF AF 22 22
					39 00 00 40 00 00 07 A2 AF AF AF AF 22 22
					39 00 00 40 00 00 07 A3 AF AF AF AF 22 22
					39 00 00 40 00 00 07 A4 AF AF AF AF 22 22
					39 00 00 40 00 00 07 A5 AF AF BC BC 22 22
					39 00 00 40 00 00 07 A6 C0 C0 C0 C0 22 22
					39 00 00 40 00 00 07 A7 CA CA 00 00 22 00
					39 00 00 40 00 00 04 FF 5A A5 52
					39 00 00 40 00 00 07 80 5E 2C B4 AA 11 00
					39 00 00 40 00 00 07 81 A0 A0 96 96 00 00
					39 00 00 40 00 00 07 82 8C 8C 82 82 00 00
					39 00 00 40 00 00 07 83 82 78 78 6E 00 00
					39 00 00 40 00 00 07 84 6E 64 64 64 00 00
					39 00 00 40 00 00 07 85 5A 5A 5B 5B 00 00
					39 00 00 40 00 00 07 86 5C 5C 5C 5C 00 00
					39 00 00 40 00 00 07 87 4D 4D 00 00 11 00
					39 00 00 40 00 00 04 FF 5A A5 53
					39 00 00 40 00 00 03 85 CC E3
					39 00 00 40 00 00 04 FF 5A A5 00
					15 00 00 40 00 00 02 60 01 //DC 120hz
					39 00 00 40 00 00 04 FF 5A A5 2D
					39 00 00 40 00 00 03 84 00 00
					15 00 00 40 00 00 02 F2 00
					39 00 00 00 00 00 04 FF 5A A5 00
				];
				qcom,mdss-dsi-lhbm-pressed-icon-on-command = [
					39 00 00 40 00 00 04 FF 5A A5 00
					15 00 00 40 00 00 02 96 09
					15 00 00 40 00 00 02 97 5B
					39 00 00 00 00 00 02 6E 03
				];
				qcom,mdss-dsi-lhbm-pressed-icon-off-command = [
					39 00 00 40 00 00 04 FF 5A A5 00
					39 00 00 00 00 00 02 6E 00
				];
				qcom,mdss-dsi-lp1-command = [
					39 00 00 40 00 00 04 FF 5A A5 00
					15 00 00 40 00 00 01 39
					39 00 00 40 00 00 04 FF 5A A5 2D
					15 00 00 40 00 00 03 8A 00 00
					/* AOD lv switch */
					39 00 00 40 00 00 04 FF 5A A5 00
					39 00 00 00 00 00 05 51 0D BB 0D BB
				];
				qcom,mdss-dsi-nolp-command = [
					39 00 00 40 00 00 04 FF 5A A5 00
					15 00 00 40 00 00 01 38
					39 00 00 00 00 00 05 51 00 00 00 00
				];
				qcom,mdss-dsi-aod-off-pwm-mode2-command = [
				];
				qcom,mdss-dsi-aod-off-compensation-command = [
				];
				qcom,mdss-dsi-aod-off-compensation-onepulse-command = [
				];
				qcom,mdss-dsi-aod-high-mode-command = [
					39 00 00 40 00 00 04 FF 5A A5 00
					39 00 00 00 00 00 05 51 0D BB 0D BB
				];
				qcom,mdss-dsi-aod-low-mode-command = [
					39 00 00 40 00 00 04 FF 5A A5 00
					39 00 00 00 00 00 05 51 0D BB 00 03
				];
				qcom,mdss-dsi-ultra-low-power-aod-on-command = [
					39 00 00 40 00 00 04 FF 5A A5 2D
					39 00 00 40 00 00 03 8A 02 00
					39 00 00 00 00 00 04 FF 5A A5 00
				];
				qcom,mdss-dsi-ultra-low-power-aod-off-command = [
					39 00 00 40 00 00 04 FF 5A A5 2D
					39 00 00 40 00 00 03 8A 00 00
					39 00 00 00 00 00 04 FF 5A A5 00
				];
				qcom,mdss-dsi-hbm-max-command = [
					39 00 00 00 00 00 03 51 10 ED
				];
				qcom,mdss-dsi-hbm-exit-max-command = [
					39 00 00 00 00 00 03 51 0F FE
				];
				qcom,mdss-dsi-lp1-command-state = "dsi_hs_mode";
				qcom,mdss-dsi-nolp-command-state = "dsi_hs_mode";
				qcom,mdss-dsi-aod-off-pwm-mode2-command-state = "dsi_hs_mode";
				qcom,mdss-dsi-aod-off-compensation-command-state = "dsi_lp_mode";
				qcom,mdss-dsi-aod-off-compensation-onepulse-command-state = "dsi_lp_mode";
				qcom,mdss-dsi-nolp-hpwm-command-state = "dsi_lp_mode";
				qcom,mdss-dsi-hbm-on-command-state = "dsi_hs_mode";
				qcom,mdss-dsi-hbm-off-command-state = "dsi_hs_mode";
				qcom,mdss-dsi-panel-read-register-open-state = "dsi_lp_mode";
				qcom,mdss-dsi-panel-read-register-close-state = "dsi_lp_mode";
				qcom,mdss-dsi-lhbm-pressed-icon-gamma-command-state = "dsi_lp_mode";
				qcom,mdss-dsi-lhbm-pressed-icon-grayscale-command-state = "dsi_lp_mode";
				qcom,mdss-dsi-lhbm-pressed-icon-on-command-state = "dsi_lp_mode";
				qcom,mdss-dsi-lhbm-pressed-icon-off-command-state = "dsi_lp_mode";
				qcom,mdss-dsi-lhbm-dbv-alpha-command-state = "dsi_hs_mode";

				qcom,mdss-dsi-reset-scanline-command-state = "dsi_hs_mode";
				qcom,mdss-dsi-recovery-scanline-command-state = "dsi_hs_mode";

				qcom,mdss-dsi-osc-track-on-command-state = "dsi_hs_mode";
				qcom,mdss-dsi-osc-track-off-command-state = "dsi_hs_mode";
				qcom,mdss-dsi-hbm-max-command-state = "dsi_hs_mode";
				qcom,mdss-dsi-hbm-exit-max-command-state = "dsi_hs_mode";

				qcom,lm-split = <608 608>;
				qcom,compression-mode = "dsc";
				qcom,mdss-dsc-encoders = <2>;
				qcom,mdss-dsc-slice-height = <20>;
				qcom,mdss-dsc-slice-width = <608>;
				qcom,mdss-dsc-slice-per-pkt = <2>;
				qcom,mdss-dsc-bit-per-component = <10>;
				qcom,mdss-dsc-bit-per-pixel = <8>;
				qcom,mdss-dsc-block-prediction-enable;
			};
		};
	};
};

&soc {
	dsi_panel_AA594_P_7_A0020_dsc_cmd_evt {
		qcom,dsi-display-active;
	};
};

&dsi_panel_AA594_P_7_A0020_dsc_cmd_evt {
	qcom,panel-supply-entries = <&oplus_dsi_panel_custom_pwr_supply>;
	qcom,platform-te-gpio = <&tlmm 86 0>;
	qcom,platform-reset-gpio = <&tlmm 98 0>;
	oplus,panel-gpio1 = <&pm8550ve_f_gpios 7 0>;

	oplus,panel-reset-position = <0x02>;
	oplus,panel-power-on-sequence = "1", "vddio", "3", "gpio1", "3", "vci", "10";
	oplus,panel-power-off-sequence = "1", "vci", "3", "gpio1", "3", "vddio", "1";

	//enable mipi strength
	oplus,enhance_mipi_strength;

	/* BRIGHTNESS CONFIG */
	qcom,mdss-dsi-bl-pmic-control-type = "bl_ctrl_dcs";
	qcom,bl-update-flag = "delay_until_first_frame";
	qcom,mdss-dsi-bl-inverted-dbv;
	qcom,mdss-dsi-bl-min-level = <1>;
	qcom,mdss-dsi-bl-max-level = <4094>;
	qcom,mdss-brightness-max-level = <4094>;
	oplus,dsi-bl-normal-max-level = <3515>;
	oplus,dsi-brightness-normal-max-level = <3515>;
	oplus,dsi-dc-backlight-threshold = <1960>;
	oplus,dsi-brightness-default-level = <1433>;

	/* ESD CONFIG */
	qcom,esd-check-enabled;
	oplus,esd-check-flag-enabled;
	qcom,mdss-dsi-panel-status-check-mode = "reg_read";
	qcom,mdss-dsi-panel-status-command = [
		06 00 00 00 00 00 01 0A
	];
	qcom,mdss-dsi-panel-status-command-state = "dsi_lp_mode";
	qcom,mdss-dsi-panel-status-value = <
		0x9C
	>;
	qcom,mdss-dsi-panel-status-read-length = <1>;
	oplus,mdss-dsi-panel-status-match-modes = <0x00000000>;

	/* MIPI ERR check config */
	/*  BIT(0): enable/disable check
	 ** BIT(1): enable/disable page switch
	 */
	oplus,mipi-err-check-config = <0x03>; // 0b0000'0011
	oplus,mipi-err-check-reg = [
		0E
	];
	oplus,mipi-err-check-value = [
		80
	];
	oplus,mipi-err-check-count = [
		01
	];

	/* FACTORY CONFIG */
	oplus,mdss-dsi-vendor-name = "A0020";
	oplus,mdss-dsi-manufacture = "P_7";
	oplus,color_vivid_status;
	oplus,color_srgb_status;
	oplus,color_softiris_status;
	oplus,color_dual_brightness_status;
	oplus,color_2nit_status;
	oplus,color_oplus_calibrate_status;
	oplus,color_samsung_status;
	oplus,color_loading_status;
	oplus,color_nature_profession_status;
	oplus,mdss-dsi-panel-type = <2>;

	/* OPLUS FEATURES CONFIG */
	oplus,dsi-serial-number-enabled;
	oplus,dsi-serial-number-switch-page;
	oplus,dsi-serial-number-index= <0>;
	oplus,dsi-serial-number-reg= <0x82>;
	oplus,dsi-serial-number-read-count= <7>;
	oplus,dsi-serial-number-base-year = <2021>;
	qcom,ulps-enabled;
	qcom,dsi-select-clocks = "pll_byte_clk0", "pll_dsi_clk0";

	oplus,vreg_ctrl_flag;

	/* btb-sn config */
	oplus,dsi-btb-sn-enabled;
	oplus,dsi-btb-sn-switch-page;
	oplus,dsi-btb-sn-reg= <0x80>;
	oplus,dsi-btb-sn-index= <0>;
	oplus,dsi-btb-sn-read-count= <32>;

	/* ofp config */
	oplus,ofp-fp-type = <0x490>;
	oplus,ofp-longrui-aod-config = <0x06>;
	oplus,ofp-need-to-wait-data-before-aod-on;
	/* adfr config */
	oplus,adfr-config = <0x3041>;
	oplus,adfr-test-te-gpio = <&tlmm 85 0>;
	/* just for qsync enable*/
	qcom,qsync-enable;
	qcom,mdss-dsi-qsync-min-refresh-rate = <30>;
	oplus,adfr-oa-use-fixed-te;

	// qcom,dsi-dyn-clk-enable;

	qcom,mdss-dsi-display-timings {
		timing@sa_fhd_120 {
			qcom,mdss-dsi-panel-phy-timings = [00 24 0A 0A 1A 19 09 0A 09 02 04 00 1E 0F];
			qcom,display-topology = <1 1 1>,<2 2 1>;
			qcom,default-topology-index = <1>;
		};
		timing@sa_fhd_90 {
			qcom,mdss-dsi-panel-phy-timings = [00 24 0A 0A 1A 19 09 0A 09 02 04 00 1E 0F];
			qcom,display-topology = <1 1 1>,<2 2 1>;
			qcom,default-topology-index = <1>;
		};
		timing@sa_fhd_60 {
			qcom,mdss-dsi-panel-phy-timings = [00 24 0A 0A 1A 19 09 0A 09 02 04 00 1E 0F];
			qcom,display-topology = <1 1 1>,<2 2 1>;
			qcom,default-topology-index = <1>;
		};
		timing@oa_fhd_120 {
			qcom,mdss-dsi-panel-phy-timings = [00 24 0A 0A 1A 19 09 0A 09 02 04 00 1E 0F];
			qcom,display-topology = <1 1 1>,<2 2 1>;
			qcom,default-topology-index = <1>;
		};
	};
};

&dsi_panel_AA594_P_7_A0020_dsc_cmd_evt {
	qcom,mdss-dsi-display-timings {
		timing@sa_fhd_120 { /* FHD+ 120hz 1094.4Mbps */
			/* standard adfr */
			qcom,disable-rsc-solver;
			qcom,mdss-dsi-h-sync-skew = <0>;
			oplus,adfr-min-fps-mapping-table = <120 60 30 20 10 1>;

			qcom,mdss-dsi-adfr-min-fps-0-command = [
				39 00 00 40 00 00 04 FF 5A A5 2D
				39 00 00 40 00 00 03 83 00 00
				39 00 00 00 00 00 04 FF 5A A5 00
			];
			qcom,mdss-dsi-adfr-min-fps-1-command = [
				39 00 00 40 00 00 04 FF 5A A5 2D
				39 00 00 40 00 00 03 83 01 00
				39 00 00 00 00 00 04 FF 5A A5 00
			];
			qcom,mdss-dsi-adfr-min-fps-2-command = [
				39 00 00 40 00 00 04 FF 5A A5 2D
				39 00 00 40 00 00 03 83 03 00
				39 00 00 00 00 00 04 FF 5A A5 00
			];
			qcom,mdss-dsi-adfr-min-fps-3-command = [
				39 00 00 40 00 00 04 FF 5A A5 2D
				39 00 00 40 00 00 03 83 04 00
				39 00 00 00 00 00 04 FF 5A A5 00
			];
			qcom,mdss-dsi-adfr-min-fps-4-command = [
				39 00 00 40 00 00 04 FF 5A A5 2D
				39 00 00 40 00 00 03 83 0B 00
				39 00 00 00 00 00 04 FF 5A A5 00
			];
			qcom,mdss-dsi-adfr-min-fps-5-command = [
				39 00 00 40 00 00 04 FF 5A A5 2D
				39 00 00 40 00 00 03 83 77 00
				39 00 00 00 00 00 04 FF 5A A5 00
			];
			qcom,mdss-dsi-hpwm-adfr-min-fps-0-command = [
				39 00 00 40 00 00 04 FF 5A A5 2D
				39 00 00 40 00 00 03 83 00 00
				39 00 00 00 00 00 04 FF 5A A5 00
			];
			qcom,mdss-dsi-hpwm-adfr-min-fps-1-command = [
				39 00 00 40 00 00 04 FF 5A A5 2D
				39 00 00 40 00 00 03 83 01 00
				39 00 00 00 00 00 04 FF 5A A5 00
			];
			qcom,mdss-dsi-hpwm-adfr-min-fps-2-command = [
				39 00 00 40 00 00 04 FF 5A A5 2D
				39 00 00 40 00 00 03 83 03 00
				39 00 00 00 00 00 04 FF 5A A5 00
			];
			qcom,mdss-dsi-hpwm-adfr-min-fps-3-command = [
				39 00 00 40 00 00 04 FF 5A A5 2D
				39 00 00 40 00 00 03 83 04 00
				39 00 00 00 00 00 04 FF 5A A5 00
			];
			qcom,mdss-dsi-hpwm-adfr-min-fps-4-command = [
				39 00 00 40 00 00 04 FF 5A A5 2D
				39 00 00 40 00 00 03 83 0B 00
				39 00 00 00 00 00 04 FF 5A A5 00
			];
			qcom,mdss-dsi-hpwm-adfr-min-fps-5-command = [
				39 00 00 40 00 00 04 FF 5A A5 2D
				39 00 00 40 00 00 03 83 77 00
				39 00 00 00 00 00 04 FF 5A A5 00
			];
			qcom,mdss-dsi-bigdc-adfr-min-fps-0-command = [
				39 00 00 40 00 00 04 FF 5A A5 2D
				39 00 00 40 00 00 03 84 00 00
				39 00 00 00 00 00 04 FF 5A A5 00
			];
			qcom,mdss-dsi-bigdc-adfr-min-fps-1-command = [
				39 00 00 40 00 00 04 FF 5A A5 2D
				39 00 00 40 00 00 03 84 01 00
				39 00 00 00 00 00 04 FF 5A A5 00
			];
			qcom,mdss-dsi-bigdc-adfr-min-fps-2-command = [
				39 00 00 40 00 00 04 FF 5A A5 2D
				39 00 00 40 00 00 03 84 03 00
				39 00 00 00 00 00 04 FF 5A A5 00
			];
			qcom,mdss-dsi-bigdc-adfr-min-fps-3-command = [
				39 00 00 40 00 00 04 FF 5A A5 2D
				39 00 00 40 00 00 03 84 04 00
				39 00 00 00 00 00 04 FF 5A A5 00
			];
			qcom,mdss-dsi-bigdc-adfr-min-fps-4-command = [
				39 00 00 40 00 00 04 FF 5A A5 2D
				39 00 00 40 00 00 03 84 0B 00
				39 00 00 00 00 00 04 FF 5A A5 00
			];
			qcom,mdss-dsi-bigdc-adfr-min-fps-5-command = [
				39 00 00 40 00 00 04 FF 5A A5 2D
				39 00 00 40 00 00 03 84 77 00
				39 00 00 00 00 00 04 FF 5A A5 00
			];

			qcom,mdss-dsi-adfr-min-fps-0-command-state = "dsi_hs_mode";
			qcom,mdss-dsi-adfr-min-fps-1-command-state = "dsi_hs_mode";
			qcom,mdss-dsi-adfr-min-fps-2-command-state = "dsi_hs_mode";
			qcom,mdss-dsi-adfr-min-fps-3-command-state = "dsi_hs_mode";
			qcom,mdss-dsi-adfr-min-fps-4-command-state = "dsi_hs_mode";
			qcom,mdss-dsi-adfr-min-fps-5-command-state = "dsi_hs_mode";
			qcom,mdss-dsi-hpwm-adfr-min-fps-0-command-state = "dsi_hs_mode";
			qcom,mdss-dsi-hpwm-adfr-min-fps-1-command-state = "dsi_hs_mode";
			qcom,mdss-dsi-hpwm-adfr-min-fps-2-command-state = "dsi_hs_mode";
			qcom,mdss-dsi-hpwm-adfr-min-fps-3-command-state = "dsi_hs_mode";
			qcom,mdss-dsi-hpwm-adfr-min-fps-4-command-state = "dsi_hs_mode";
			qcom,mdss-dsi-hpwm-adfr-min-fps-5-command-state = "dsi_hs_mode";
			qcom,mdss-dsi-bigdc-adfr-min-fps-0-command-state = "dsi_hs_mode";
			qcom,mdss-dsi-bigdc-adfr-min-fps-1-command-state = "dsi_hs_mode";
			qcom,mdss-dsi-bigdc-adfr-min-fps-2-command-state = "dsi_hs_mode";
			qcom,mdss-dsi-bigdc-adfr-min-fps-3-command-state = "dsi_hs_mode";
			qcom,mdss-dsi-bigdc-adfr-min-fps-4-command-state = "dsi_hs_mode";
			qcom,mdss-dsi-bigdc-adfr-min-fps-5-command-state = "dsi_hs_mode";
		};
		timing@sa_fhd_90 { /* FHD+ 120hz 1094.4Mbps */
			/* standard adfr */
			qcom,mdss-dsi-h-sync-skew = <0>;
			oplus,adfr-min-fps-mapping-table = <90 45 30 15 10 1>;

			qcom,mdss-dsi-adfr-min-fps-0-command = [
				39 00 00 40 00 00 04 FF 5A A5 2D
				39 00 00 40 00 00 03 85 00 00
				39 00 00 00 00 00 04 FF 5A A5 00
			];
			qcom,mdss-dsi-adfr-min-fps-1-command = [
				39 00 00 40 00 00 04 FF 5A A5 2D
				39 00 00 40 00 00 03 85 01 00
				39 00 00 00 00 00 04 FF 5A A5 00
			];
			qcom,mdss-dsi-adfr-min-fps-2-command = [
				39 00 00 40 00 00 04 FF 5A A5 2D
				39 00 00 40 00 00 03 85 02 00
				39 00 00 00 00 00 04 FF 5A A5 00
			];
			qcom,mdss-dsi-adfr-min-fps-3-command = [
				39 00 00 40 00 00 04 FF 5A A5 2D
				39 00 00 40 00 00 03 85 03 00
				39 00 00 00 00 00 04 FF 5A A5 00
			];
			qcom,mdss-dsi-adfr-min-fps-4-command = [
				39 00 00 40 00 00 04 FF 5A A5 2D
				39 00 00 40 00 00 03 85 08 00
				39 00 00 00 00 00 04 FF 5A A5 00
			];
			qcom,mdss-dsi-adfr-min-fps-5-command = [
				39 00 00 40 00 00 04 FF 5A A5 2D
				39 00 00 40 00 00 03 85 59 00
				39 00 00 00 00 00 04 FF 5A A5 00
			];
			qcom,mdss-dsi-hpwm-adfr-min-fps-0-command = [
				39 00 00 40 00 00 04 FF 5A A5 2D
				39 00 00 40 00 00 03 85 00 00
				39 00 00 00 00 00 04 FF 5A A5 00
			];
			qcom,mdss-dsi-hpwm-adfr-min-fps-1-command = [
				39 00 00 40 00 00 04 FF 5A A5 2D
				39 00 00 40 00 00 03 85 01 00
				39 00 00 00 00 00 04 FF 5A A5 00
			];
			qcom,mdss-dsi-hpwm-adfr-min-fps-2-command = [
				39 00 00 40 00 00 04 FF 5A A5 2D
				39 00 00 40 00 00 03 85 02 00
				39 00 00 00 00 00 04 FF 5A A5 00
			];
			qcom,mdss-dsi-hpwm-adfr-min-fps-3-command = [
				39 00 00 40 00 00 04 FF 5A A5 2D
				39 00 00 40 00 00 03 85 03 00
				39 00 00 00 00 00 04 FF 5A A5 00
			];
			qcom,mdss-dsi-hpwm-adfr-min-fps-4-command = [
				39 00 00 40 00 00 04 FF 5A A5 2D
				39 00 00 40 00 00 03 85 08 00
				39 00 00 00 00 00 04 FF 5A A5 00
			];
			qcom,mdss-dsi-hpwm-adfr-min-fps-5-command = [
				39 00 00 40 00 00 04 FF 5A A5 2D
				39 00 00 40 00 00 03 85 59 00
				39 00 00 00 00 00 04 FF 5A A5 00
			];
			qcom,mdss-dsi-bigdc-adfr-min-fps-0-command = [
				39 00 00 40 00 00 04 FF 5A A5 2D
				39 00 00 40 00 00 03 86 00 00
				39 00 00 00 00 00 04 FF 5A A5 00
			];
			qcom,mdss-dsi-bigdc-adfr-min-fps-1-command = [
				39 00 00 40 00 00 04 FF 5A A5 2D
				39 00 00 40 00 00 03 86 01 00
				39 00 00 00 00 00 04 FF 5A A5 00
			];
			qcom,mdss-dsi-bigdc-adfr-min-fps-2-command = [
				39 00 00 40 00 00 04 FF 5A A5 2D
				39 00 00 40 00 00 03 86 02 00
				39 00 00 00 00 00 04 FF 5A A5 00
			];
			qcom,mdss-dsi-bigdc-adfr-min-fps-3-command = [
				39 00 00 40 00 00 04 FF 5A A5 2D
				39 00 00 40 00 00 03 86 03 00
				39 00 00 00 00 00 04 FF 5A A5 00
			];
			qcom,mdss-dsi-bigdc-adfr-min-fps-4-command = [
				39 00 00 40 00 00 04 FF 5A A5 2D
				39 00 00 40 00 00 03 86 08 00
				39 00 00 00 00 00 04 FF 5A A5 00
			];
			qcom,mdss-dsi-bigdc-adfr-min-fps-5-command = [
				39 00 00 40 00 00 04 FF 5A A5 2D
				39 00 00 40 00 00 03 86 59 00
				39 00 00 00 00 00 04 FF 5A A5 00
			];

			qcom,mdss-dsi-adfr-min-fps-0-command-state = "dsi_hs_mode";
			qcom,mdss-dsi-adfr-min-fps-1-command-state = "dsi_hs_mode";
			qcom,mdss-dsi-adfr-min-fps-2-command-state = "dsi_hs_mode";
			qcom,mdss-dsi-adfr-min-fps-3-command-state = "dsi_hs_mode";
			qcom,mdss-dsi-adfr-min-fps-4-command-state = "dsi_hs_mode";
			qcom,mdss-dsi-adfr-min-fps-5-command-state = "dsi_hs_mode";
			qcom,mdss-dsi-hpwm-adfr-min-fps-0-command-state = "dsi_hs_mode";
			qcom,mdss-dsi-hpwm-adfr-min-fps-1-command-state = "dsi_hs_mode";
			qcom,mdss-dsi-hpwm-adfr-min-fps-2-command-state = "dsi_hs_mode";
			qcom,mdss-dsi-hpwm-adfr-min-fps-3-command-state = "dsi_hs_mode";
			qcom,mdss-dsi-hpwm-adfr-min-fps-4-command-state = "dsi_hs_mode";
			qcom,mdss-dsi-hpwm-adfr-min-fps-5-command-state = "dsi_hs_mode";
			qcom,mdss-dsi-bigdc-adfr-min-fps-0-command-state = "dsi_hs_mode";
			qcom,mdss-dsi-bigdc-adfr-min-fps-1-command-state = "dsi_hs_mode";
			qcom,mdss-dsi-bigdc-adfr-min-fps-2-command-state = "dsi_hs_mode";
			qcom,mdss-dsi-bigdc-adfr-min-fps-3-command-state = "dsi_hs_mode";
			qcom,mdss-dsi-bigdc-adfr-min-fps-4-command-state = "dsi_hs_mode";
			qcom,mdss-dsi-bigdc-adfr-min-fps-5-command-state = "dsi_hs_mode";
		};
		timing@sa_fhd_60 { /* FHD+ 120hz 1094.4Mbps */
			/* standard adfr */
			qcom,mdss-dsi-h-sync-skew = <1>;
			oplus,adfr-min-fps-mapping-table = <60 30 20 10 1>;

			qcom,mdss-dsi-adfr-min-fps-0-command = [
				39 00 00 40 00 00 04 FF 5A A5 2D
				39 00 00 40 00 00 03 83 01 00
				39 00 00 00 00 00 04 FF 5A A5 00
			];
			qcom,mdss-dsi-adfr-min-fps-1-command = [
				39 00 00 40 00 00 04 FF 5A A5 2D
				39 00 00 40 00 00 03 83 03 00
				39 00 00 00 00 00 04 FF 5A A5 00
			];
			qcom,mdss-dsi-adfr-min-fps-2-command = [
				39 00 00 40 00 00 04 FF 5A A5 2D
				39 00 00 40 00 00 03 83 04 00
				39 00 00 00 00 00 04 FF 5A A5 00
			];
			qcom,mdss-dsi-adfr-min-fps-3-command = [
				39 00 00 40 00 00 04 FF 5A A5 2D
				39 00 00 40 00 00 03 83 0B 00
				39 00 00 00 00 00 04 FF 5A A5 00
			];
			qcom,mdss-dsi-adfr-min-fps-4-command = [
				39 00 00 40 00 00 04 FF 5A A5 2D
				39 00 00 40 00 00 03 83 77 00
				39 00 00 00 00 00 04 FF 5A A5 00
			];
			qcom,mdss-dsi-hpwm-adfr-min-fps-0-command = [
				39 00 00 40 00 00 04 FF 5A A5 2D
				39 00 00 40 00 00 03 83 01 00
				39 00 00 00 00 00 04 FF 5A A5 00
			];
			qcom,mdss-dsi-hpwm-adfr-min-fps-1-command = [
				39 00 00 40 00 00 04 FF 5A A5 2D
				39 00 00 40 00 00 03 83 03 00
				39 00 00 00 00 00 04 FF 5A A5 00
			];
			qcom,mdss-dsi-hpwm-adfr-min-fps-2-command = [
				39 00 00 40 00 00 04 FF 5A A5 2D
				39 00 00 40 00 00 03 83 04 00
				39 00 00 00 00 00 04 FF 5A A5 00
			];
			qcom,mdss-dsi-hpwm-adfr-min-fps-3-command = [
				39 00 00 40 00 00 04 FF 5A A5 2D
				39 00 00 40 00 00 03 83 0B 00
				39 00 00 00 00 00 04 FF 5A A5 00
			];
			qcom,mdss-dsi-hpwm-adfr-min-fps-4-command = [
				39 00 00 40 00 00 04 FF 5A A5 2D
				39 00 00 40 00 00 03 83 77 00
				39 00 00 00 00 00 04 FF 5A A5 00
			];
			qcom,mdss-dsi-bigdc-adfr-min-fps-0-command = [
				39 00 00 40 00 00 04 FF 5A A5 2D
				39 00 00 40 00 00 03 84 01 00
				39 00 00 00 00 00 04 FF 5A A5 00
			];
			qcom,mdss-dsi-bigdc-adfr-min-fps-1-command = [
				39 00 00 40 00 00 04 FF 5A A5 2D
				39 00 00 40 00 00 03 84 03 00
				39 00 00 00 00 00 04 FF 5A A5 00
			];
			qcom,mdss-dsi-bigdc-adfr-min-fps-2-command = [
				39 00 00 40 00 00 04 FF 5A A5 2D
				39 00 00 40 00 00 03 84 04 00
				39 00 00 00 00 00 04 FF 5A A5 00
			];
			qcom,mdss-dsi-bigdc-adfr-min-fps-3-command = [
				39 00 00 40 00 00 04 FF 5A A5 2D
				39 00 00 40 00 00 03 84 0B 00
				39 00 00 00 00 00 04 FF 5A A5 00
			];
			qcom,mdss-dsi-bigdc-adfr-min-fps-4-command = [
				39 00 00 40 00 00 04 FF 5A A5 2D
				39 00 00 40 00 00 03 84 77 00
				39 00 00 00 00 00 04 FF 5A A5 00
			];

			qcom,mdss-dsi-adfr-min-fps-0-command-state = "dsi_hs_mode";
			qcom,mdss-dsi-adfr-min-fps-1-command-state = "dsi_hs_mode";
			qcom,mdss-dsi-adfr-min-fps-2-command-state = "dsi_hs_mode";
			qcom,mdss-dsi-adfr-min-fps-3-command-state = "dsi_hs_mode";
			qcom,mdss-dsi-adfr-min-fps-4-command-state = "dsi_hs_mode";
			qcom,mdss-dsi-hpwm-adfr-min-fps-0-command-state = "dsi_hs_mode";
			qcom,mdss-dsi-hpwm-adfr-min-fps-1-command-state = "dsi_hs_mode";
			qcom,mdss-dsi-hpwm-adfr-min-fps-2-command-state = "dsi_hs_mode";
			qcom,mdss-dsi-hpwm-adfr-min-fps-3-command-state = "dsi_hs_mode";
			qcom,mdss-dsi-hpwm-adfr-min-fps-4-command-state = "dsi_hs_mode";
			qcom,mdss-dsi-bigdc-adfr-min-fps-0-command-state = "dsi_hs_mode";
			qcom,mdss-dsi-bigdc-adfr-min-fps-1-command-state = "dsi_hs_mode";
			qcom,mdss-dsi-bigdc-adfr-min-fps-2-command-state = "dsi_hs_mode";
			qcom,mdss-dsi-bigdc-adfr-min-fps-3-command-state = "dsi_hs_mode";
			qcom,mdss-dsi-bigdc-adfr-min-fps-4-command-state = "dsi_hs_mode";
		};
		timing@oa_fhd_120 { /* FHD+ 120hz 1094.4Mbps */
			/* oplus adfr */
			qcom,mdss-dsi-h-sync-skew = <2>;
			oplus,adfr-min-fps-mapping-table = <120 30>;

			qcom,mdss-dsi-qsync-on-commands = [
				39 00 00 00 00 00 04 FF 5A A5 00
			];
			qcom,mdss-dsi-qsync-off-commands = [
				39 00 00 00 00 00 04 FF 5A A5 00
			];
			qcom,mdss-dsi-adfr-min-fps-0-command = [
				39 00 00 40 00 00 04 FF 5A A5 2D
				39 00 00 40 00 00 03 83 00 00
				39 00 00 00 00 00 04 FF 5A A5 00
			];
			qcom,mdss-dsi-adfr-min-fps-1-command = [
				39 00 00 40 00 00 04 FF 5A A5 2D
				39 00 00 40 00 00 03 83 03 00
				39 00 00 00 00 00 04 FF 5A A5 00
			];
			qcom,mdss-dsi-hpwm-adfr-min-fps-0-command = [
				39 00 00 40 00 00 04 FF 5A A5 2D
				39 00 00 40 00 00 03 83 00 00
				39 00 00 00 00 00 04 FF 5A A5 00
			];
			qcom,mdss-dsi-hpwm-adfr-min-fps-1-command = [
				39 00 00 40 00 00 04 FF 5A A5 2D
				39 00 00 40 00 00 03 83 03 00
				39 00 00 00 00 00 04 FF 5A A5 00
			];
			qcom,mdss-dsi-bigdc-adfr-min-fps-0-command = [
				39 00 00 40 00 00 04 FF 5A A5 2D
				39 00 00 40 00 00 03 84 00 00
				39 00 00 00 00 00 04 FF 5A A5 00
			];
			qcom,mdss-dsi-bigdc-adfr-min-fps-1-command = [
				39 00 00 40 00 00 04 FF 5A A5 2D
				39 00 00 40 00 00 03 84 03 00
				39 00 00 00 00 00 04 FF 5A A5 00
			];
			qcom,mdss-dsi-qsync-on-commands-state ="dsi_hs_mode";
			qcom,mdss-dsi-qsync-off-commands-state ="dsi_hs_mode";
			qcom,mdss-dsi-adfr-min-fps-0-command-state = "dsi_hs_mode";
			qcom,mdss-dsi-adfr-min-fps-1-command-state = "dsi_hs_mode";
			qcom,mdss-dsi-hpwm-adfr-min-fps-0-command-state = "dsi_hs_mode";
			qcom,mdss-dsi-hpwm-adfr-min-fps-1-command-state = "dsi_hs_mode";
			qcom,mdss-dsi-bigdc-adfr-min-fps-0-command-state = "dsi_hs_mode";
			qcom,mdss-dsi-bigdc-adfr-min-fps-1-command-state = "dsi_hs_mode";
		};
	};
};

&dsi_panel_AA594_P_7_A0020_dsc_cmd_evt {
	qcom,panel_voltage_vddi_name = "vddio";
	qcom,panel_voltage_vddi = <0 1800000 1850000 1950000>;
	qcom,panel_voltage_vddr_name = "vddio";
	qcom,panel_voltage_vddr = <1 1800000 1850000 1950000>;
};

&dsi_panel_AA594_P_7_A0020_dsc_cmd_evt{
	/* demura dbv config */

	/* pwm config */
	/*	oplus,pwm-switch-config:
		Bit0: pwm feature enable
		Bit1: pwm mode switch enable, need to config switch cmds
		Bit2: force enabled pwm mode switch cmd, will send mode cmd even dbv threshold cmd feature is configed
		Bit3: pwm dbv threshold pulse switch enable, need to config threshold switch cmds
		Bit4: wait te before sending pwm dbv threshold pulse switch cmd
		Bit5: replace specific cmd to other cmd while in pwm 1pulse mode
		Bit6: sending extend cmd while panel power on accroding to current pwm mode
		Bit7: sending extend cmd while timing switch accroding to current pwm pulse level
		Bit8: sending extend cmd after sending dbv threshold cmd in another thread
		...
		Bit24:support pwm mode0
		Bit25:support pwm mode1
		Bit26:support pwm mode2
	*/
	oplus,pwm-switch-config = <0x06000067>;
	/*	oplus,pwm-switch-mode0-states-info/oplus,pwm-switch-mode1-states-info:
		Specific dbv threshold and pulse info of 2 pwm mode, for pulse, 0 symbols 1pulse,
		1symbols 3pulse and 2 symbols 18pulse. The format should be 1 dbv threshold info with
		2 pwm pulse levels left and right(for example, <2 1087 1> means 18pulse while dbv <= 1087
		and 3pulse while dbv > 1087), or only one pulse level, no threshold.
	*/
	oplus,pwm-switch-mode1-states-info = <2 1162 0>;
	oplus,pwm-switch-mode2-states-info = <0>;
	/*	oplus,pwm-mode1-cmd-switch-map/oplus,pwm-mode2-cmd-switch-map;
		Specific cmd replace relationship while in switch on(1pulse) mode. It is a string array that
		compose with cmd names, every 2 names combine 1 map. For example, map "'a', 'b'" means replace
		a to b while sending a in switch on mode.
	*/
	oplus,pwm-mode2-cmd-switch-map = "qcom,mdss-dsi-nolp-command", "qcom,mdss-dsi-aod-off-pwm-mode2-command",
			"qcom,mdss-dsi-timing-switch-command", "qcom,mdss-dsi-timming-switch-pwm-mode2-command";
	/* SPR CONFIG */
	qcom,spr-pack-type = "pentile";
};
